[part 1 of 2: packages /CAN3/ISignalGroup to /CAN3/Cluster]
AUTOSAR XML (schema 4-3-0)
package /CAN3/ISignalGroup
  30 x i signal group:
    CAN3_SG_BMS1: i-signal=[CAN3_BMSChckSum_1, CAN3_BMSRolCnct_1, CAN3_HVBPwrAvailChrg, CAN3_HVBPwrAvailChrg30, CAN3_HVBPwrAvailChrg60, CAN3_HVBPwrAvailDchrg, CAN3_HVBPwrAvailDchrg30, CAN3_HVBPwrAvailDchrg60, CAN3_HVBattCurr, CAN3_HVBattVolt], system-signal-group=CAN3_SG_BMS1
    CAN3_SG_BMS2: i-signal=[CAN3_HVInVolt, CAN3_LVBattDet12V, CAN3_OBCDCCurLm, CAN3_OBCDCVoltLm, CAN3_ReChargerStaFromEvcc], system-signal-group=CAN3_SG_BMS2
    CAN3_SG_BMS3: i-signal=[CAN3_ACChrgCurrDis, CAN3_BMS_HVBattCellBalance_Sta, CAN3_Battsystfail_Num, CAN3_CellType, CAN3_HVBChrgPwr, CAN3_HVBChrgPwrTotal, CAN3_HVBDrvPwr, CAN3_HVBDrvPwrTotal, CAN3_HVBFullChrgPwr, CAN3_HVBIsoImpedenceN, CAN3_HVBIsoImpedenceP, CAN3_HVBSOH, CAN3_HVBattPackVolt, CAN3_HVBattSOC, CAN3_HVBattSOCDiff, CAN3_HVBattSOCDis, CAN3_RechrgCyc, CAN3_RemainChrgTime, CAN3_SOC_UseLimit], system-signal-group=CAN3_SG_BMS3
    CAN3_SG_BMS4: i-signal=[CAN3_CellTempAvg, CAN3_HVBCellVoltMax, CAN3_HVBCellVoltMin, CAN3_HVBMTempMax, CAN3_HVBMTempMin, CAN3_MaxCellTemp_Num, CAN3_MaxCellVolt_Num, CAN3_MinCellTemp_Num, CAN3_MinCellVolt_Num, CAN3_Mtemp01, CAN3_Mtemp02, CAN3_Mtemp03, CAN3_Mtemp04, CAN3_Mtemp05, CAN3_Mtemp06, CAN3_Mtemp07, CAN3_Mtemp08, CAN3_Mtemp09, CAN3_Mtemp10, CAN3_Mtemp11, CAN3_Mtemp12, CAN3_Mtemp13, CAN3_Mtemp14, CAN3_Mtemp15, CAN3_Mtemp16, CAN3_Mtemp17, CAN3_Mtemp18, CAN3_Mtemp19, CAN3_Mtemp20], system-signal-group=CAN3_SG_BMS4
    CAN3_SG_BMS6: i-signal=[CAN3_BMSChckSum, CAN3_BMSRolCnct, CAN3_BMS_READY, CAN3_BMS_Warn_1, CAN3_BMS_Warn_2, CAN3_BMS_Warn_3, CAN3_BMS_Warn_4, CAN3_BMS_Warn_5, CAN3_BMS_Warn_6, CAN3_BMS_Warn_7, CAN3_BMS_Warn_8, CAN3_CellUnconsistErr, CAN3_ChrgInLockReq, CAN3_ChrgPlugSta, CAN3_DCChrgSysShockErr, CAN3_DisChrgPlugErr, CAN3_ExtChrgSta, CAN3_HVBCellOvrVoltErr, CAN3_HVBCellOvrVoltWarn, CAN3_HVBCellUdrVoltWarn, CAN3_HVBCellUnbalanErr, CAN3_HVBCellUndrVoltErr, CAN3_HVBChrgErr, CAN3_HVBContactorSta, CAN3_HVBHVILErr, CAN3_HVBOvrChrgCurrErr, CAN3_HVBOvrDchrgCurErr, CAN3_HVBOvrSOCErr, CAN3_HVBOvrTempErr, CAN3_HVBOvrTempWarn, CAN3_HVBOvrVoltErr, CAN3_HVBPrechrgSta, CAN3_HVBPreheatPrecoolSta, CAN3_HVBSOCJumpError, CAN3_HVBShrtChrgCurrErr, CAN3_HVBShrtDischrgCurrErr, CAN3_HVBTempDiffErr, CAN3_HVBUndrSOCErr, CAN3_HVBUndrTempErr, CAN3_HVBUndrTempWarn, CAN3_HVBUndrVoltErr, CAN3_HVBattReady4Pre, CAN3_HVILSta, CAN3_IsoDetSta, CAN3_SystemUncomErr, CAN3_V2LSta], system-signal-group=CAN3_SG_BMS6
    CAN3_SG_BMS7: i-signal=[CAN3_ChrgCurType, CAN3_ChrgLampSta, CAN3_FireDetErr, CAN3_HVBattErr], system-signal-group=CAN3_SG_BMS7
    CAN3_SG_CCU1: i-signal=[CAN3_CS_CCU1, CAN3_DCDCAuxVolt, CAN3_DCDCInVoltInf, CAN3_DCDCPreCompleted, CAN3_OBCDCCurrInf, CAN3_OBCDCVoltInf, CAN3_OBCPreCompleted, CAN3_OBCWakeup4Plugin, CAN3_RC_CCU1], system-signal-group=CAN3_SG_CCU1
    CAN3_SG_CCU2: i-signal=[CAN3_CS_CCU2, CAN3_DCDCEnaSta, CAN3_DCDCFaultSta, CAN3_DCDCReady4Pre, CAN3_DCDCTemp, CAN3_OBCACCurrInf, CAN3_OBCACVoltInf, CAN3_OBCDCP, CAN3_OBCEnaSta, CAN3_OBCFaultSta, CAN3_OBCPluginSta, CAN3_OBCReady4Pre, CAN3_OBCTemp, CAN3_OBCV2LSta, CAN3_OBC_AC_Cur_Lim, CAN3_RC_CCU2, CAN3_ReqOBCV2LEna], system-signal-group=CAN3_SG_CCU2
    CAN3_SG_CCU4: i-signal=[CAN3_DCDCAuxCur, CAN3_DCDCHVCur, CAN3_OBCV2LINVOTP, CAN3_OBCV2LInsuFault, CAN3_OBCV2LVinOVP, CAN3_OBCV2LVinUVP, CAN3_OBCV2LVoutOCP, CAN3_OBCV2LVoutOVP, CAN3_OBCV2LVoutUVP], system-signal-group=CAN3_SG_CCU4
    CAN3_SG_FD_BCM1: i-signal=[CAN3_AllDoorSW, CAN3_AntiTheftSeatFold, CAN3_AntitheftSta, CAN3_BCM_Buzzer_Req, CAN3_BCM_DoorLock_Sta, CAN3_BrakeLamp, CAN3_CTDCtrl, CAN3_CTDLockSW, CAN3_CTDUnlockSW, CAN3_CrashDetd, CAN3_Dimmer, CAN3_DimmerEN, CAN3_DoorLockIND, CAN3_DrDoorSW, CAN3_Fr_ChargingDoorCtrl, CAN3_Fr_FogLamp, CAN3_Fr_Wiper_H, CAN3_Fr_Wiper_L, CAN3_H_Beam, CAN3_HazardSW, CAN3_HoodSW, CAN3_HornCtrl, CAN3_LBSD, CAN3_LDRL, CAN3_LTurnLP, CAN3_L_APM_WdwEnable, CAN3_L_Beam, CAN3_LockSetting, CAN3_MirrorCtrl, CAN3_MirrorDefog, CAN3_PmicBootReason, CAN3_PosLamp, CAN3_PsDoorSW, CAN3_RBSD, CAN3_RDRL, CAN3_RLDoorSW, CAN3_RRDoorSW, CAN3_RTurnLP, CAN3_ReverseLamp, CAN3_RoomLampH, CAN3_RoomLampL, CAN3_Rr_ChargingDoorCtrl, CAN3_Rr_Defog, CAN3_Rr_FogLamp, CAN3_Rr_Wiper, CAN3_TailgateHDSW, CAN3_TailgateRemote, CAN3_Tailgate_SW, CAN3_TrunkRel, CAN3_WasherCtrl, CAN3_WiperFixMode, CAN3_WisrBootReason], system-signal-group=CAN3_SG_FD_BCM1
    CAN3_SG_FD_OTA1: i-signal=[CAN3_OTA_DL_Available, CAN3_OTA_DL_Speed, CAN3_OTA_InVehicle_FW, CAN3_OTA_Lock_Req, CAN3_OTA_MDA_Status, CAN3_OTA_Mode, CAN3_OTA_Network_Type, CAN3_OTA_Progress_Rate, CAN3_OTA_TBOXResetReq, CAN3_OTA_Up_Backcount, CAN3_OTA_Update_Available, CAN3_OTA_Updating_ECU], system-signal-group=CAN3_SG_FD_OTA1
    CAN3_SG_FD_THCM1: i-signal=[CAN3_BatteryMode, CAN3_CCU_ACLampSts, CAN3_CCU_ACMaxLampSts, CAN3_CCU_AutoLampSts, CAN3_CCU_AutoMidLampSts, CAN3_CCU_Dispaly_Request, CAN3_CCU_EcoSts, CAN3_CCU_FrtOnOffLampSts, CAN3_CCU_HEATMaxLampSts, CAN3_CCU_RrOnOffLampSts, CAN3_CCU_SyncLampSts, CAN3_CabinMode, CAN3_EDriveMode, CAN3_FD_AGS_Cmd, CAN3_FD_RecyAuto_Cmd, CAN3_Fr_Coolantflow, CAN3_Fr_Coolanttemp, CAN3_HPThermalRecoveryReq, CAN3_Rr_Coolantflow, CAN3_Rr_Coolanttemp, CAN3_sigAirIntenZon1St, CAN3_sigAirIntenZon3St, CAN3_sigAmbAirT, CAN3_sigCbnAirT, CAN3_sigCbnPTCPwrAct, CAN3_sigCbnSolarLeft, CAN3_sigCbnSolarRight, CAN3_sigClmtCmprPwrAct, CAN3_sigClntTHvBattOut, CAN3_sigDfrstSt, CAN3_sigHvacSt, CAN3_sigRecircSt, CAN3_sigSetTempZon1St, CAN3_sigSetTempZon2St, CAN3_sigSetTempZon3St, CAN3_sigWindDirZon1St, CAN3_sigWindDirZon3St], system-signal-group=CAN3_SG_FD_THCM1
    CAN3_SG_FD_THCM2: i-signal=[CAN3_ACSubMode, CAN3_APTC_ActFrRiPwr, CAN3_BatLoopActWtFlw, CAN3_CCU_CbnPreACWkSts, CAN3_CCU_CbnPreEstimdTi, CAN3_CCU_CbnPreSts, CAN3_CCU_HiVoltageReq, CAN3_CoolgFanActDuty, CAN3_DeiceModReq, CAN3_FD_Blower_Cmd, CAN3_FD_Comp_Cmd, CAN3_FD_EWP1_Cmd, CAN3_FD_EWP2_Cmd, CAN3_FD_EWP3_Cmd, CAN3_FD_EXV1_Cmd, CAN3_FD_EXV2_Cmd, CAN3_FD_FWV_Cmd, CAN3_FD_FrLeAPTCHeatPwr_Cmd, CAN3_FD_FrRiAPTCHeatPwr_Cmd, CAN3_FD_FrWPTCHeatPwr_Cmd, CAN3_FD_RrAPTCHeatPwr_Cmd, CAN3_FD_SOTXV_Cmd, CAN3_FD_SOV1_Cmd, CAN3_FD_SOV2_Cmd, CAN3_FD_SOV3_Cmd, CAN3_FD_TWV_Cmd], system-signal-group=CAN3_SG_FD_THCM2
    CAN3_SG_FD_V2L1: i-signal=[CAN3_Req_OBCV2LEna, CAN3_Req_V2LSwOn, CAN3_Req_V2L_IVI_Popup], system-signal-group=CAN3_SG_FD_V2L1
    CAN3_SG_FD_VCU0: i-signal=[CAN3_EVCCAplusPwrUpReq, CAN3_FDADC12VDet, CAN3_FDADC12VDetAvg, CAN3_FDC_VCU_ActMaxSlideRate_Sta, CAN3_FDC_VCU_AllowMovThd_OTA_Sta, CAN3_FDC_VCU_DTCCarousel_Sta, CAN3_FDC_VCU_ForceP_Cmd, CAN3_FDC_VCU_PwrReq_OTA_Sta, CAN3_FDC_VCU_RWDRDCActive_Sta, CAN3_FDC_VCU_RegenTqLimitEn_Sta, CAN3_FDC_VCU_SlideRegenLimTq_Sta, CAN3_FDC_VCU_VehActSpd_Sta, CAN3_FDC_VCU_VehMalfunLevel_Sta, CAN3_FDC_VMC_ActStESCYaw_Sta, CAN3_FDC_VMC_AntiSpdLimEn_Sta, CAN3_FDC_VMC_LongAcc_Sta, CAN3_Fr_TqSource, CAN3_HVRlyOpFail, CAN3_HVTHCMSysAvail, CAN3_LVBattChrgtimeAct, CAN3_LVBattVoltSta, CAN3_LVChrgHoldTAct, CAN3_LVSilentChrgLv, CAN3_LVSilentChrgReq, CAN3_LVSilentChrgSta, CAN3_MCUActDisFail, CAN3_PMMAllowECUSleep, CAN3_PowerDownFault, CAN3_PowerDownState, CAN3_PowerUpFault, CAN3_PowerUpState, CAN3_PwrDownReq, CAN3_PwrStaConstraint, CAN3_PwrStaONTOIVIPopReq, CAN3_PwrStaONTOIVIPopT, CAN3_PwrStaSelect, CAN3_PwrStaTOSta, CAN3_PwrUpReq, CAN3_Rr_TqSource, CAN3_SchedChgTOSta, CAN3_SilentChkAllowSleep, CAN3_SysAllowReadySta, CAN3_SysPwrSta, CAN3_TCountSta, CAN3_TimerAllowSleep, CAN3_VCUBrkSWSta, CAN3_VCUFLDoorSta, CAN3_VCUFRDoorSta, CAN3_VCURLDoorSta, CAN3_VCURRDoorSta, CAN3_VehHVPwrAvail4THCM], system-signal-group=CAN3_SG_FD_VCU0
    CAN3_SG_FD_VCU1:
      com-based-signal-group-transformations=E2E_PROFILE_01_CAN3_SG_FD_VCU1
      i-signal=[CAN3_ActiveDischReq, CAN3_CS_VCU1, CAN3_CoastDwModeStaChk, CAN3_DCDCEnaReq, CAN3_DCDCVoltSetpoint, CAN3_DemoModeStaChk, CAN3_Dr_SeatSta, CAN3_DynoModeStaChk, CAN3_Fr_ActvDmpDisabReq, CAN3_Fr_MCUEnaReq, CAN3_HVBatCnctReq, CAN3_HVSysReadyToCharge, CAN3_LVChrgFuncStaChk, CAN3_MSA_Crl_Sta, CAN3_PrkReq, CAN3_PwrSta, CAN3_RC_VCU1, CAN3_Rr_ActvDmpDisabReq, CAN3_Rr_MCUEnaReq, CAN3_ShiftGearPosn]
      system-signal-group=CAN3_SG_FD_VCU1
      end-to-end-transformation-i-signal-props{transformer=Technology_E2E_PROFILE_01_CAN3_SG_FD_VCU1, data-ids=13815, data-length=64}
    CAN3_SG_FD_VCU2: i-signal=[CAN3_CS_VCU2_CAN1, CAN3_Fr_IdcMax, CAN3_Fr_IdcMin, CAN3_Fr_TMTqReq, CAN3_Fr_TorqMax, CAN3_Fr_TorqMin, CAN3_Fr_UdcMax, CAN3_Fr_UdcMin, CAN3_RC_VCU2_CAN1, CAN3_Rr_IdcMax, CAN3_Rr_IdcMin, CAN3_Rr_TMTqReq, CAN3_Rr_TorqMax, CAN3_Rr_TorqMin, CAN3_Rr_UdcMax, CAN3_Rr_UdcMin], system-signal-group=CAN3_SG_FD_VCU2
    CAN3_SG_MCU_F1: i-signal=[CAN3_Fr_ActvDmpDisabSta, CAN3_Fr_EDUDrtSta, CAN3_Fr_EDUOpratingSta, CAN3_Fr_EDURealTMTq, CAN3_Fr_EDURotateDirction, CAN3_Fr_EDUTqReqFbk, CAN3_Fr_MCU1Chksum, CAN3_Fr_MCU1RolCnt, CAN3_Fr_MCUBAT, CAN3_Fr_MCUDCBusCurr, CAN3_Fr_MCUDCBusVolt, CAN3_Fr_MCUDischrgSta, CAN3_Fr_MCUEnaSta, CAN3_Fr_MCUErr, CAN3_Fr_MCUIGN_sta, CAN3_Fr_MCUReady, CAN3_Fr_MCUReady4Pre, CAN3_Fr_MCUSysSta, CAN3_Fr_MCUTemp, CAN3_Fr_MotorAvailTq, CAN3_Fr_RegenAvailTq, CAN3_Fr_Reserved_bits, CAN3_Fr_TMSpd, CAN3_Fr_TMTemp, CAN3_Fr_TMid, CAN3_Fr_TMiq, CAN3_MCUWarn_F], system-signal-group=CAN3_SG_MCU_F1
    CAN3_SG_MCU_F2: i-signal=[CAN3_Fr_CoolanttempReq, CAN3_Fr_EOP_SpdSet, CAN3_Fr_Failcode1, CAN3_Fr_Failcode2, CAN3_Fr_Failcodehistory1, CAN3_Fr_Failcodehistory2, CAN3_Fr_LLCTemp, CAN3_Fr_LLCflowReq, CAN3_Fr_MCU2Chksum, CAN3_Fr_MCU2RolCnt, CAN3_Fr_MCUTempWarn, CAN3_Fr_TMTempWarn, CAN3_MCU_F_ResetCnt_Sta], system-signal-group=CAN3_SG_MCU_F2
    CAN3_SG_MCU_R1: i-signal=[CAN3_MCUWarn_R, CAN3_Rr_ActvDmpDisabSta, CAN3_Rr_EDUDrtSta, CAN3_Rr_EDUOpratingSta, CAN3_Rr_EDURealTMTq, CAN3_Rr_EDURotateDirction, CAN3_Rr_EDUTqReqFbk, CAN3_Rr_MCU1Chksum, CAN3_Rr_MCU1RolCnt, CAN3_Rr_MCUBAT, CAN3_Rr_MCUDCBusCurr, CAN3_Rr_MCUDCBusVolt, CAN3_Rr_MCUDischrgSta, CAN3_Rr_MCUEnaSta, CAN3_Rr_MCUErr, CAN3_Rr_MCUIGN_sta, CAN3_Rr_MCUReady, CAN3_Rr_MCUReady4Pre, CAN3_Rr_MCUSysSta, CAN3_Rr_MCUTemp, CAN3_Rr_MotorAvailTq, CAN3_Rr_RegenAvailTq, CAN3_Rr_Reserved_bits, CAN3_Rr_TMSpd, CAN3_Rr_TMTemp, CAN3_Rr_TMid, CAN3_Rr_TMiq], system-signal-group=CAN3_SG_MCU_R1
    CAN3_SG_MCU_R2: i-signal=[CAN3_MCU_R_ResetCnt_Sta, CAN3_Rr_CoolanttempReq, CAN3_Rr_EOP_SpdSet, CAN3_Rr_Failcode1, CAN3_Rr_Failcode2, CAN3_Rr_Failcodehistory1, CAN3_Rr_Failcodehistory2, CAN3_Rr_LLCTemp, CAN3_Rr_LLCflowReq, CAN3_Rr_MCU2Chksum, CAN3_Rr_MCU2RolCnt, CAN3_Rr_MCUTempWarn, CAN3_Rr_TMTempWarn], system-signal-group=CAN3_SG_MCU_R2
    CAN3_SG_Shifter1: i-signal=[CAN3_Shifter_CRC8, CAN3_Shifter_Fail_sta, CAN3_Shifter_Handle_Cmd, CAN3_Shifter_RC], system-signal-group=CAN3_SG_Shifter1
    CAN3_SG_XNMm_BMS: i-signal=[CAN3_NM_BMS_Active_WU, CAN3_NM_BMS_CSB, CAN3_NM_BMS_ERROR_State, CAN3_NM_BMS_Node_ID, CAN3_NM_BMS_PNI, CAN3_NM_BMS_Rpt_Msg_Req], system-signal-group=CAN3_SG_XNMm_BMS
    CAN3_SG_XNMm_CCU: i-signal=[CAN3_NM_CCU_Active_WU, CAN3_NM_CCU_CSB, CAN3_NM_CCU_ERROR_State, CAN3_NM_CCU_Node_ID, CAN3_NM_CCU_PNI, CAN3_NM_CCU_Rpt_Msg_Req], system-signal-group=CAN3_SG_XNMm_CCU
    CAN3_SG_XNMm_EOP_F: i-signal=[CAN3_NM_EOP_F_Active_WU, CAN3_NM_EOP_F_CSB, CAN3_NM_EOP_F_ERROR_State, CAN3_NM_EOP_F_Node_ID, CAN3_NM_EOP_F_PNI, CAN3_NM_EOP_F_Rpt_Msg_Req], system-signal-group=CAN3_SG_XNMm_EOP_F
    CAN3_SG_XNMm_EOP_R: i-signal=[CAN3_NM_EOP_R_Active_WU, CAN3_NM_EOP_R_CSB, CAN3_NM_EOP_R_ERROR_State, CAN3_NM_EOP_R_Node_ID, CAN3_NM_EOP_R_PNI, CAN3_NM_EOP_R_Rpt_Msg_Req], system-signal-group=CAN3_SG_XNMm_EOP_R
    CAN3_SG_XNMm_FUSION: i-signal=[CAN3_NM_FUSION_Active_WU, CAN3_NM_FUSION_CSB, CAN3_NM_FUSION_ERROR_State, CAN3_NM_FUSION_Node_ID, CAN3_NM_FUSION_PNI, CAN3_NM_FUSION_Rpt_Msg_Req], system-signal-group=CAN3_SG_XNMm_FUSION
    CAN3_SG_XNMm_MCU_F: i-signal=[CAN3_NM_MCU_F_Active_WU, CAN3_NM_MCU_F_CSB, CAN3_NM_MCU_F_ERROR_State, CAN3_NM_MCU_F_Node_ID, CAN3_NM_MCU_F_PNI, CAN3_NM_MCU_F_Rpt_Msg_Req], system-signal-group=CAN3_SG_XNMm_MCU_F
    CAN3_SG_XNMm_MCU_R: i-signal=[CAN3_NM_MCU_R_Active_WU, CAN3_NM_MCU_R_CSB, CAN3_NM_MCU_R_ERROR_State, CAN3_NM_MCU_R_Node_ID, CAN3_NM_MCU_R_PNI, CAN3_NM_MCU_R_Rpt_Msg_Req], system-signal-group=CAN3_SG_XNMm_MCU_R
    CAN3_SG_XNMm_Shifter: i-signal=[CAN3_NM_Shifter_Active_WU, CAN3_NM_Shifter_CSB, CAN3_NM_Shifter_ERROR_State, CAN3_NM_Shifter_Node_ID, CAN3_NM_Shifter_PNI, CAN3_NM_Shifter_Rpt_Msg_Req], system-signal-group=CAN3_SG_XNMm_Shifter
package /CAN3/Cluster
  can cluster CAN3: baudrate=500, can-fd-baudrate=2000
    can physical channel CAN3: comm-connectors=ConnCAN3
      frame CAN3_BMS1: id 0x171, frame-length=16, can-addressing-mode=STANDARD, can-fd-frame-support=true, can-frame-rx-behavior=CAN-FD, can-frame-tx-behavior=CAN-FD
        pdu CAN3_BMS1: length=16, minimum-delay=0.0, transmission-mode-true-timing=cyclic-timing=time-period=0.01, unused-bit-pattern=0
          mapping CAN3_SG_BMS1: i-signal-group=CAN3_SG_BMS1, start-position=0, transfer-property=PENDING
          signal CAN3_BMSChckSum_1: start 7, 8 bit, big-endian, i-signal-type=PRIMITIVE, init-value=constant-reference=Init_CAN3_BMSChckSum_1, base-type=uint8, implementation-data-type=uint8, transfer-property=PENDING
          signal CAN3_BMSRolCnct_1: start 15, 4 bit, big-endian, i-signal-type=PRIMITIVE, init-value=constant-reference=Init_CAN3_BMSRolCnct_1, base-type=uint8, implementation-data-type=uint8, transfer-property=PENDING
          signal CAN3_HVBPwrAvailChrg: start 91, 12 bit, big-endian, i-signal-type=PRIMITIVE, init-value=constant-reference=Init_CAN3_HVBPwrAvailChrg, base-type=uint16, implementation-data-type=uint16, transfer-property=PENDING
          signal CAN3_HVBPwrAvailChrg30: start 115, 12 bit, big-endian, i-signal-type=PRIMITIVE, init-value=constant-reference=Init_CAN3_HVBPwrAvailChrg30, base-type=uint16, implementation-data-type=uint16, transfer-property=PENDING
          signal CAN3_HVBPwrAvailChrg60: start 67, 12 bit, big-endian, i-signal-type=PRIMITIVE, init-value=constant-reference=Init_CAN3_HVBPwrAvailChrg60, base-type=uint16, implementation-data-type=uint16, transfer-property=PENDING
          signal CAN3_HVBPwrAvailDchrg: start 87, 12 bit, big-endian, i-signal-type=PRIMITIVE, init-value=constant-reference=Init_CAN3_HVBPwrAvailDchrg, base-type=uint16, implementation-data-type=uint16, transfer-property=PENDING
          signal CAN3_HVBPwrAvailDchrg30: start 111, 12 bit, big-endian, i-signal-type=PRIMITIVE, init-value=constant-reference=Init_CAN3_HVBPwrAvailDchrg30, base-type=uint16, implementation-data-type=uint16, transfer-property=PENDING
          signal CAN3_HVBPwrAvailDchrg60: start 63, 12 bit, big-endian, i-signal-type=PRIMITIVE, init-value=constant-reference=Init_CAN3_HVBPwrAvailDchrg60, base-type=uint16, implementation-data-type=uint16, transfer-property=PENDING
          signal CAN3_HVBattCurr: start 46, 15 bit, big-endian, i-signal-type=PRIMITIVE, init-value=constant-reference=Init_CAN3_HVBattCurr, base-type=uint16, implementation-data-type=uint16, transfer-property=PENDING
          signal CAN3_HVBattVolt: start 28, 13 bit, big-endian, i-signal-type=PRIMITIVE, init-value=constant-reference=Init_CAN3_HVBattVolt, base-type=uint16, implementation-data-type=uint16, transfer-property=PENDING
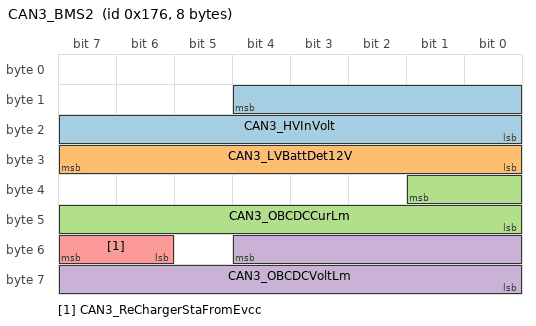
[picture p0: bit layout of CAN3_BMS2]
      frame CAN3_BMS2: id 0x176, frame-length=8, can-addressing-mode=STANDARD, can-fd-frame-support=true, can-frame-rx-behavior=CAN-FD, can-frame-tx-behavior=CAN-FD
        pdu CAN3_BMS2: length=8, minimum-delay=0.0, transmission-mode-true-timing={cyclic-timing=time-period=0.1, event-controlled-timing={number-of-repetitions=0, repetition-period=0.01}}, unused-bit-pattern=0
          mapping CAN3_SG_BMS2: i-signal-group=CAN3_SG_BMS2, start-position=0, transfer-property=TRIGGERED-ON-CHANGE
          signal CAN3_HVInVolt: start 12, 13 bit, big-endian, i-signal-type=PRIMITIVE, init-value=constant-reference=Init_CAN3_HVInVolt, base-type=uint16, implementation-data-type=uint16, transfer-property=PENDING
          signal CAN3_LVBattDet12V: start 31, 8 bit, big-endian, i-signal-type=PRIMITIVE, init-value=constant-reference=Init_CAN3_LVBattDet12V, base-type=uint8, implementation-data-type=uint8, transfer-property=PENDING
          signal CAN3_OBCDCCurLm: start 33, 10 bit, big-endian, i-signal-type=PRIMITIVE, init-value=constant-reference=Init_CAN3_OBCDCCurLm, base-type=uint16, implementation-data-type=uint16, transfer-property=PENDING
          signal CAN3_OBCDCVoltLm: start 52, 13 bit, big-endian, i-signal-type=PRIMITIVE, init-value=constant-reference=Init_CAN3_OBCDCVoltLm, base-type=uint16, implementation-data-type=uint16, transfer-property=PENDING
          signal CAN3_ReChargerStaFromEvcc: start 55, 2 bit, big-endian, i-signal-type=PRIMITIVE, init-value=constant-reference=Init_CAN3_ReChargerStaFromEvcc, base-type=uint8, implementation-data-type=uint8, transfer-property=TRIGGERED-ON-CHANGE
      frame CAN3_BMS3: id 0x329, frame-length=32, can-addressing-mode=STANDARD, can-fd-frame-support=true, can-frame-rx-behavior=CAN-FD, can-frame-tx-behavior=CAN-FD
        pdu CAN3_BMS3: length=32, minimum-delay=0.0, transmission-mode-true-timing=cyclic-timing=time-period=1, unused-bit-pattern=0
          mapping CAN3_SG_BMS3: i-signal-group=CAN3_SG_BMS3, start-position=0, transfer-property=PENDING
          signal CAN3_ACChrgCurrDis: start 86, 15 bit, big-endian, i-signal-type=PRIMITIVE, init-value=constant-reference=Init_CAN3_ACChrgCurrDis, base-type=uint16, implementation-data-type=uint16, transfer-property=PENDING
          signal CAN3_BMS_HVBattCellBalance_Sta: start 200, 1 bit, big-endian, i-signal-type=PRIMITIVE, init-value=constant-reference=Init_CAN3_BMS_HVBattCellBalance_Sta, base-type=uint8, implementation-data-type=uint8, transfer-property=PENDING
          signal CAN3_Battsystfail_Num: start 127, 8 bit, big-endian, i-signal-type=PRIMITIVE, init-value=constant-reference=Init_CAN3_Battsystfail_Num, base-type=uint8, implementation-data-type=uint8, transfer-property=PENDING
          signal CAN3_CellType: start 101, 4 bit, big-endian, i-signal-type=PRIMITIVE, init-value=constant-reference=Init_CAN3_CellType, base-type=uint8, implementation-data-type=uint8, transfer-property=PENDING
          signal CAN3_HVBChrgPwr: start 223, 10 bit, big-endian, i-signal-type=PRIMITIVE, init-value=constant-reference=Init_CAN3_HVBChrgPwr, base-type=uint16, implementation-data-type=uint16, transfer-property=PENDING
          signal CAN3_HVBChrgPwrTotal: start 57, 18 bit, big-endian, i-signal-type=PRIMITIVE, init-value=constant-reference=Init_CAN3_HVBChrgPwrTotal, base-type=uint32, implementation-data-type=uint32, transfer-property=PENDING
          signal CAN3_HVBDrvPwr: start 199, 10 bit, big-endian, i-signal-type=PRIMITIVE, init-value=constant-reference=Init_CAN3_HVBDrvPwr, base-type=uint16, implementation-data-type=uint16, transfer-property=PENDING
          signal CAN3_HVBDrvPwrTotal: start 33, 18 bit, big-endian, i-signal-type=PRIMITIVE, init-value=constant-reference=Init_CAN3_HVBDrvPwrTotal, base-type=uint32, implementation-data-type=uint32, transfer-property=PENDING
          signal CAN3_HVBFullChrgPwr: start 177, 10 bit, big-endian, i-signal-type=PRIMITIVE, init-value=constant-reference=Init_CAN3_HVBFullChrgPwr, base-type=uint16, implementation-data-type=uint16, transfer-property=PENDING
          signal CAN3_HVBIsoImpedenceN: start 134, 15 bit, big-endian, i-signal-type=PRIMITIVE, init-value=constant-reference=Init_CAN3_HVBIsoImpedenceN, base-type=uint16, implementation-data-type=uint16, transfer-property=PENDING
          signal CAN3_HVBIsoImpedenceP: start 150, 15 bit, big-endian, i-signal-type=PRIMITIVE, init-value=constant-reference=Init_CAN3_HVBIsoImpedenceP, base-type=uint16, implementation-data-type=uint16, transfer-property=PENDING
          signal CAN3_HVBSOH: start 167, 8 bit, big-endian, i-signal-type=PRIMITIVE, init-value=constant-reference=Init_CAN3_HVBSOH, base-type=uint8, implementation-data-type=uint8, transfer-property=PENDING
          signal CAN3_HVBattPackVolt: start 228, 13 bit, big-endian, i-signal-type=PRIMITIVE, init-value=constant-reference=Init_CAN3_HVBattPackVolt, base-type=uint16, implementation-data-type=uint16, transfer-property=PENDING
          signal CAN3_HVBattSOC: start 247, 8 bit, big-endian, i-signal-type=PRIMITIVE, init-value=constant-reference=Init_CAN3_HVBattSOC, base-type=uint8, implementation-data-type=uint8, transfer-property=PENDING
          signal CAN3_HVBattSOCDiff: start 213, 6 bit, big-endian, i-signal-type=PRIMITIVE, init-value=constant-reference=Init_CAN3_HVBattSOCDiff, base-type=uint8, implementation-data-type=uint8, transfer-property=PENDING
          signal CAN3_HVBattSOCDis: start 255, 8 bit, big-endian, i-signal-type=PRIMITIVE, init-value=constant-reference=Init_CAN3_HVBattSOCDis, base-type=uint8, implementation-data-type=uint8, transfer-property=PENDING
          signal CAN3_RechrgCyc: start 97, 18 bit, big-endian, i-signal-type=PRIMITIVE, init-value=constant-reference=Init_CAN3_RechrgCyc, base-type=uint32, implementation-data-type=uint32, transfer-property=PENDING
          signal CAN3_RemainChrgTime: start 175, 12 bit, big-endian, i-signal-type=PRIMITIVE, init-value=constant-reference=Init_CAN3_RemainChrgTime, base-type=uint16, implementation-data-type=uint16, transfer-property=PENDING
          signal CAN3_SOC_UseLimit: start 215, 2 bit, big-endian, i-signal-type=PRIMITIVE, init-value=constant-reference=Init_CAN3_SOC_UseLimit, base-type=uint8, implementation-data-type=uint8, transfer-property=PENDING
      frame CAN3_BMS4: id 0x3E0, frame-length=48, can-addressing-mode=STANDARD, can-fd-frame-support=true, can-frame-rx-behavior=CAN-FD, can-frame-tx-behavior=CAN-FD
        pdu CAN3_BMS4: length=48, minimum-delay=0.0, transmission-mode-true-timing=cyclic-timing=time-period=0.1, unused-bit-pattern=0
          mapping CAN3_SG_BMS4: i-signal-group=CAN3_SG_BMS4, start-position=0, transfer-property=PENDING
          signal CAN3_CellTempAvg: start 351, 8 bit, big-endian, i-signal-type=PRIMITIVE, init-value=constant-reference=Init_CAN3_CellTempAvg, base-type=uint8, implementation-data-type=uint8, transfer-property=PENDING
          signal CAN3_HVBCellVoltMax: start 375, 16 bit, big-endian, i-signal-type=PRIMITIVE, init-value=constant-reference=Init_CAN3_HVBCellVoltMax, base-type=uint16, implementation-data-type=uint16, transfer-property=PENDING
          signal CAN3_HVBCellVoltMin: start 359, 16 bit, big-endian, i-signal-type=PRIMITIVE, init-value=constant-reference=Init_CAN3_HVBCellVoltMin, base-type=uint16, implementation-data-type=uint16, transfer-property=PENDING
          signal CAN3_HVBMTempMax: start 311, 8 bit, big-endian, i-signal-type=PRIMITIVE, init-value=constant-reference=Init_CAN3_HVBMTempMax, base-type=uint8, implementation-data-type=uint8, transfer-property=PENDING
          signal CAN3_HVBMTempMin: start 303, 8 bit, big-endian, i-signal-type=PRIMITIVE, init-value=constant-reference=Init_CAN3_HVBMTempMin, base-type=uint8, implementation-data-type=uint8, transfer-property=PENDING
          signal CAN3_MaxCellTemp_Num: start 327, 8 bit, big-endian, i-signal-type=PRIMITIVE, init-value=constant-reference=Init_CAN3_MaxCellTemp_Num, base-type=uint8, implementation-data-type=uint8, transfer-property=PENDING
          signal CAN3_MaxCellVolt_Num: start 343, 8 bit, big-endian, i-signal-type=PRIMITIVE, init-value=constant-reference=Init_CAN3_MaxCellVolt_Num, base-type=uint8, implementation-data-type=uint8, transfer-property=PENDING
          signal CAN3_MinCellTemp_Num: start 319, 8 bit, big-endian, i-signal-type=PRIMITIVE, init-value=constant-reference=Init_CAN3_MinCellTemp_Num, base-type=uint8, implementation-data-type=uint8, transfer-property=PENDING
          signal CAN3_MinCellVolt_Num: start 335, 8 bit, big-endian, i-signal-type=PRIMITIVE, init-value=constant-reference=Init_CAN3_MinCellVolt_Num, base-type=uint8, implementation-data-type=uint8, transfer-property=PENDING
          signal CAN3_Mtemp01: start 119, 8 bit, big-endian, i-signal-type=PRIMITIVE, init-value=constant-reference=Init_CAN3_Mtemp01, base-type=uint8, implementation-data-type=uint8, transfer-property=PENDING
          signal CAN3_Mtemp02: start 111, 8 bit, big-endian, i-signal-type=PRIMITIVE, init-value=constant-reference=Init_CAN3_Mtemp02, base-type=uint8, implementation-data-type=uint8, transfer-property=PENDING
          signal CAN3_Mtemp03: start 103, 8 bit, big-endian, i-signal-type=PRIMITIVE, init-value=constant-reference=Init_CAN3_Mtemp03, base-type=uint8, implementation-data-type=uint8, transfer-property=PENDING
          signal CAN3_Mtemp04: start 95, 8 bit, big-endian, i-signal-type=PRIMITIVE, init-value=constant-reference=Init_CAN3_Mtemp04, base-type=uint8, implementation-data-type=uint8, transfer-property=PENDING
          signal CAN3_Mtemp05: start 87, 8 bit, big-endian, i-signal-type=PRIMITIVE, init-value=constant-reference=Init_CAN3_Mtemp05, base-type=uint8, implementation-data-type=uint8, transfer-property=PENDING
          signal CAN3_Mtemp06: start 79, 8 bit, big-endian, i-signal-type=PRIMITIVE, init-value=constant-reference=Init_CAN3_Mtemp06, base-type=uint8, implementation-data-type=uint8, transfer-property=PENDING
          signal CAN3_Mtemp07: start 71, 8 bit, big-endian, i-signal-type=PRIMITIVE, init-value=constant-reference=Init_CAN3_Mtemp07, base-type=uint8, implementation-data-type=uint8, transfer-property=PENDING
          signal CAN3_Mtemp08: start 63, 8 bit, big-endian, i-signal-type=PRIMITIVE, init-value=constant-reference=Init_CAN3_Mtemp08, base-type=uint8, implementation-data-type=uint8, transfer-property=PENDING
          signal CAN3_Mtemp09: start 55, 8 bit, big-endian, i-signal-type=PRIMITIVE, init-value=constant-reference=Init_CAN3_Mtemp09, base-type=uint8, implementation-data-type=uint8, transfer-property=PENDING
          signal CAN3_Mtemp10: start 47, 8 bit, big-endian, i-signal-type=PRIMITIVE, init-value=constant-reference=Init_CAN3_Mtemp10, base-type=uint8, implementation-data-type=uint8, transfer-property=PENDING
          signal CAN3_Mtemp11: start 39, 8 bit, big-endian, i-signal-type=PRIMITIVE, init-value=constant-reference=Init_CAN3_Mtemp11, base-type=uint8, implementation-data-type=uint8, transfer-property=PENDING
          signal CAN3_Mtemp12: start 31, 8 bit, big-endian, i-signal-type=PRIMITIVE, init-value=constant-reference=Init_CAN3_Mtemp12, base-type=uint8, implementation-data-type=uint8, transfer-property=PENDING
          signal CAN3_Mtemp13: start 23, 8 bit, big-endian, i-signal-type=PRIMITIVE, init-value=constant-reference=Init_CAN3_Mtemp13, base-type=uint8, implementation-data-type=uint8, transfer-property=PENDING
          signal CAN3_Mtemp14: start 15, 8 bit, big-endian, i-signal-type=PRIMITIVE, init-value=constant-reference=Init_CAN3_Mtemp14, base-type=uint8, implementation-data-type=uint8, transfer-property=PENDING
          signal CAN3_Mtemp15: start 7, 8 bit, big-endian, i-signal-type=PRIMITIVE, init-value=constant-reference=Init_CAN3_Mtemp15, base-type=uint8, implementation-data-type=uint8, transfer-property=PENDING
          signal CAN3_Mtemp16: start 159, 8 bit, big-endian, i-signal-type=PRIMITIVE, init-value=constant-reference=Init_CAN3_Mtemp16, base-type=uint8, implementation-data-type=uint8, transfer-property=PENDING
          signal CAN3_Mtemp17: start 151, 8 bit, big-endian, i-signal-type=PRIMITIVE, init-value=constant-reference=Init_CAN3_Mtemp17, base-type=uint8, implementation-data-type=uint8, transfer-property=PENDING
          signal CAN3_Mtemp18: start 143, 8 bit, big-endian, i-signal-type=PRIMITIVE, init-value=constant-reference=Init_CAN3_Mtemp18, base-type=uint8, implementation-data-type=uint8, transfer-property=PENDING
          signal CAN3_Mtemp19: start 135, 8 bit, big-endian, i-signal-type=PRIMITIVE, init-value=constant-reference=Init_CAN3_Mtemp19, base-type=uint8, implementation-data-type=uint8, transfer-property=PENDING
          signal CAN3_Mtemp20: start 127, 8 bit, big-endian, i-signal-type=PRIMITIVE, init-value=constant-reference=Init_CAN3_Mtemp20, base-type=uint8, implementation-data-type=uint8, transfer-property=PENDING
      frame CAN3_BMS6: id 0x17A, frame-length=12, can-addressing-mode=STANDARD, can-fd-frame-support=true, can-frame-rx-behavior=CAN-FD, can-frame-tx-behavior=CAN-FD
        pdu CAN3_BMS6: length=12, minimum-delay=0.0, transmission-mode-true-timing={cyclic-timing=time-period=0.1, event-controlled-timing={number-of-repetitions=0, repetition-period=0.01}}, unused-bit-pattern=0
          mapping CAN3_SG_BMS6: i-signal-group=CAN3_SG_BMS6, start-position=0, transfer-property=TRIGGERED-ON-CHANGE
          signal CAN3_BMSChckSum: start 7, 8 bit, big-endian, i-signal-type=PRIMITIVE, init-value=constant-reference=Init_CAN3_BMSChckSum, base-type=uint8, implementation-data-type=uint8, transfer-property=PENDING
          signal CAN3_BMSRolCnct: start 15, 4 bit, big-endian, i-signal-type=PRIMITIVE, init-value=constant-reference=Init_CAN3_BMSRolCnct, base-type=uint8, implementation-data-type=uint8, transfer-property=PENDING
          signal CAN3_BMS_READY: start 65, 1 bit, big-endian, i-signal-type=PRIMITIVE, init-value=constant-reference=Init_CAN3_BMS_READY, base-type=uint8, implementation-data-type=uint8, transfer-property=TRIGGERED-ON-CHANGE
          signal CAN3_BMS_Warn_1: start 88, 1 bit, big-endian, i-signal-type=PRIMITIVE, init-value=constant-reference=Init_CAN3_BMS_Warn_1, base-type=uint8, implementation-data-type=uint8, transfer-property=TRIGGERED-ON-CHANGE
          signal CAN3_BMS_Warn_2: start 89, 1 bit, big-endian, i-signal-type=PRIMITIVE, init-value=constant-reference=Init_CAN3_BMS_Warn_2, base-type=uint8, implementation-data-type=uint8, transfer-property=TRIGGERED-ON-CHANGE
          signal CAN3_BMS_Warn_3: start 90, 1 bit, big-endian, i-signal-type=PRIMITIVE, init-value=constant-reference=Init_CAN3_BMS_Warn_3, base-type=uint8, implementation-data-type=uint8, transfer-property=TRIGGERED-ON-CHANGE
          signal CAN3_BMS_Warn_4: start 91, 1 bit, big-endian, i-signal-type=PRIMITIVE, init-value=constant-reference=Init_CAN3_BMS_Warn_4, base-type=uint8, implementation-data-type=uint8, transfer-property=TRIGGERED-ON-CHANGE
          signal CAN3_BMS_Warn_5: start 92, 1 bit, big-endian, i-signal-type=PRIMITIVE, init-value=constant-reference=Init_CAN3_BMS_Warn_5, base-type=uint8, implementation-data-type=uint8, transfer-property=TRIGGERED-ON-CHANGE
          signal CAN3_BMS_Warn_6: start 93, 1 bit, big-endian, i-signal-type=PRIMITIVE, init-value=constant-reference=Init_CAN3_BMS_Warn_6, base-type=uint8, implementation-data-type=uint8, transfer-property=TRIGGERED-ON-CHANGE
          signal CAN3_BMS_Warn_7: start 94, 1 bit, big-endian, i-signal-type=PRIMITIVE, init-value=constant-reference=Init_CAN3_BMS_Warn_7, base-type=uint8, implementation-data-type=uint8, transfer-property=TRIGGERED-ON-CHANGE
          signal CAN3_BMS_Warn_8: start 95, 1 bit, big-endian, i-signal-type=PRIMITIVE, init-value=constant-reference=Init_CAN3_BMS_Warn_8, base-type=uint8, implementation-data-type=uint8, transfer-property=TRIGGERED-ON-CHANGE
          signal CAN3_CellUnconsistErr: start 50, 1 bit, big-endian, i-signal-type=PRIMITIVE, init-value=constant-reference=Init_CAN3_CellUnconsistErr, base-type=uint8, implementation-data-type=uint8, transfer-property=TRIGGERED-ON-CHANGE
          signal CAN3_ChrgInLockReq: start 45, 2 bit, big-endian, i-signal-type=PRIMITIVE, init-value=constant-reference=Init_CAN3_ChrgInLockReq, base-type=uint8, implementation-data-type=uint8, transfer-property=TRIGGERED-ON-CHANGE
          signal CAN3_ChrgPlugSta: start 59, 2 bit, big-endian, i-signal-type=PRIMITIVE, init-value=constant-reference=Init_CAN3_ChrgPlugSta, base-type=uint8, implementation-data-type=uint8, transfer-property=TRIGGERED-ON-CHANGE
          signal CAN3_DCChrgSysShockErr: start 64, 1 bit, big-endian, i-signal-type=PRIMITIVE, init-value=constant-reference=Init_CAN3_DCChrgSysShockErr, base-type=uint8, implementation-data-type=uint8, transfer-property=TRIGGERED-ON-CHANGE
          signal CAN3_DisChrgPlugErr: start 47, 2 bit, big-endian, i-signal-type=PRIMITIVE, init-value=constant-reference=Init_CAN3_DisChrgPlugErr, base-type=uint8, implementation-data-type=uint8, transfer-property=TRIGGERED-ON-CHANGE
          signal CAN3_ExtChrgSta: start 61, 2 bit, big-endian, i-signal-type=PRIMITIVE, init-value=constant-reference=Init_CAN3_ExtChrgSta, base-type=uint8, implementation-data-type=uint8, transfer-property=TRIGGERED-ON-CHANGE
          signal CAN3_HVBCellOvrVoltErr: start 40, 1 bit, big-endian, i-signal-type=PRIMITIVE, init-value=constant-reference=Init_CAN3_HVBCellOvrVoltErr, base-type=uint8, implementation-data-type=uint8, transfer-property=TRIGGERED-ON-CHANGE
          signal CAN3_HVBCellOvrVoltWarn: start 53, 2 bit, big-endian, i-signal-type=PRIMITIVE, init-value=constant-reference=Init_CAN3_HVBCellOvrVoltWarn, base-type=uint8, implementation-data-type=uint8, transfer-property=TRIGGERED-ON-CHANGE
          signal CAN3_HVBCellUdrVoltWarn: start 55, 2 bit, big-endian, i-signal-type=PRIMITIVE, init-value=constant-reference=Init_CAN3_HVBCellUdrVoltWarn, base-type=uint8, implementation-data-type=uint8, transfer-property=TRIGGERED-ON-CHANGE
          signal CAN3_HVBCellUnbalanErr: start 42, 1 bit, big-endian, i-signal-type=PRIMITIVE, init-value=constant-reference=Init_CAN3_HVBCellUnbalanErr, base-type=uint8, implementation-data-type=uint8, transfer-property=TRIGGERED-ON-CHANGE
          signal CAN3_HVBCellUndrVoltErr: start 41, 1 bit, big-endian, i-signal-type=PRIMITIVE, init-value=constant-reference=Init_CAN3_HVBCellUndrVoltErr, base-type=uint8, implementation-data-type=uint8, transfer-property=TRIGGERED-ON-CHANGE
          signal CAN3_HVBChrgErr: start 39, 8 bit, big-endian, i-signal-type=PRIMITIVE, init-value=constant-reference=Init_CAN3_HVBChrgErr, base-type=uint8, implementation-data-type=uint8, transfer-property=TRIGGERED-ON-CHANGE
          signal CAN3_HVBContactorSta: start 66, 1 bit, big-endian, i-signal-type=PRIMITIVE, init-value=constant-reference=Init_CAN3_HVBContactorSta, base-type=uint8, implementation-data-type=uint8, transfer-property=TRIGGERED-ON-CHANGE
          signal CAN3_HVBHVILErr: start 79, 1 bit, big-endian, i-signal-type=PRIMITIVE, init-value=constant-reference=Init_CAN3_HVBHVILErr, base-type=uint8, implementation-data-type=uint8, transfer-property=TRIGGERED-ON-CHANGE
          signal CAN3_HVBOvrChrgCurrErr: start 72, 1 bit, big-endian, i-signal-type=PRIMITIVE, init-value=constant-reference=Init_CAN3_HVBOvrChrgCurrErr, base-type=uint8, implementation-data-type=uint8, transfer-property=TRIGGERED-ON-CHANGE
          signal CAN3_HVBOvrDchrgCurErr: start 73, 1 bit, big-endian, i-signal-type=PRIMITIVE, init-value=constant-reference=Init_CAN3_HVBOvrDchrgCurErr, base-type=uint8, implementation-data-type=uint8, transfer-property=TRIGGERED-ON-CHANGE
          signal CAN3_HVBOvrSOCErr: start 76, 1 bit, big-endian, i-signal-type=PRIMITIVE, init-value=constant-reference=Init_CAN3_HVBOvrSOCErr, base-type=uint8, implementation-data-type=uint8, transfer-property=TRIGGERED-ON-CHANGE
          signal CAN3_HVBOvrTempErr: start 74, 1 bit, big-endian, i-signal-type=PRIMITIVE, init-value=constant-reference=Init_CAN3_HVBOvrTempErr, base-type=uint8, implementation-data-type=uint8, transfer-property=TRIGGERED-ON-CHANGE
          signal CAN3_HVBOvrTempWarn: start 81, 2 bit, big-endian, i-signal-type=PRIMITIVE, init-value=constant-reference=Init_CAN3_HVBOvrTempWarn, base-type=uint8, implementation-data-type=uint8, transfer-property=TRIGGERED-ON-CHANGE
          signal CAN3_HVBOvrVoltErr: start 84, 1 bit, big-endian, i-signal-type=PRIMITIVE, init-value=constant-reference=Init_CAN3_HVBOvrVoltErr, base-type=uint8, implementation-data-type=uint8, transfer-property=TRIGGERED-ON-CHANGE
          signal CAN3_HVBPrechrgSta: start 69, 2 bit, big-endian, i-signal-type=PRIMITIVE, init-value=constant-reference=Init_CAN3_HVBPrechrgSta, base-type=uint8, implementation-data-type=uint8, transfer-property=TRIGGERED-ON-CHANGE
          signal CAN3_HVBPreheatPrecoolSta: start 63, 2 bit, big-endian, i-signal-type=PRIMITIVE, init-value=constant-reference=Init_CAN3_HVBPreheatPrecoolSta, base-type=uint8, implementation-data-type=uint8, transfer-property=TRIGGERED-ON-CHANGE
          signal CAN3_HVBSOCJumpError: start 78, 1 bit, big-endian, i-signal-type=PRIMITIVE, init-value=constant-reference=Init_CAN3_HVBSOCJumpError, base-type=uint8, implementation-data-type=uint8, transfer-property=TRIGGERED-ON-CHANGE
          signal CAN3_HVBShrtChrgCurrErr: start 86, 1 bit, big-endian, i-signal-type=PRIMITIVE, init-value=constant-reference=Init_CAN3_HVBShrtChrgCurrErr, base-type=uint8, implementation-data-type=uint8, transfer-property=TRIGGERED-ON-CHANGE
          signal CAN3_HVBShrtDischrgCurrErr: start 87, 1 bit, big-endian, i-signal-type=PRIMITIVE, init-value=constant-reference=Init_CAN3_HVBShrtDischrgCurrErr, base-type=uint8, implementation-data-type=uint8, transfer-property=TRIGGERED-ON-CHANGE
          signal CAN3_HVBTempDiffErr: start 70, 1 bit, big-endian, i-signal-type=PRIMITIVE, init-value=constant-reference=Init_CAN3_HVBTempDiffErr, base-type=uint8, implementation-data-type=uint8, transfer-property=TRIGGERED-ON-CHANGE
          signal CAN3_HVBUndrSOCErr: start 77, 1 bit, big-endian, i-signal-type=PRIMITIVE, init-value=constant-reference=Init_CAN3_HVBUndrSOCErr, base-type=uint8, implementation-data-type=uint8, transfer-property=TRIGGERED-ON-CHANGE
          signal CAN3_HVBUndrTempErr: start 75, 1 bit, big-endian, i-signal-type=PRIMITIVE, init-value=constant-reference=Init_CAN3_HVBUndrTempErr, base-type=uint8, implementation-data-type=uint8, transfer-property=TRIGGERED-ON-CHANGE
          signal CAN3_HVBUndrTempWarn: start 83, 2 bit, big-endian, i-signal-type=PRIMITIVE, init-value=constant-reference=Init_CAN3_HVBUndrTempWarn, base-type=uint8, implementation-data-type=uint8, transfer-property=TRIGGERED-ON-CHANGE
          signal CAN3_HVBUndrVoltErr: start 85, 1 bit, big-endian, i-signal-type=PRIMITIVE, init-value=constant-reference=Init_CAN3_HVBUndrVoltErr, base-type=uint8, implementation-data-type=uint8, transfer-property=TRIGGERED-ON-CHANGE
          signal CAN3_HVBattReady4Pre: start 57, 2 bit, big-endian, i-signal-type=PRIMITIVE, init-value=constant-reference=Init_CAN3_HVBattReady4Pre, base-type=uint8, implementation-data-type=uint8, transfer-property=TRIGGERED-ON-CHANGE
          signal CAN3_HVILSta: start 71, 1 bit, big-endian, i-signal-type=PRIMITIVE, init-value=constant-reference=Init_CAN3_HVILSta, base-type=uint8, implementation-data-type=uint8, transfer-property=TRIGGERED-ON-CHANGE
          signal CAN3_IsoDetSta: start 48, 1 bit, big-endian, i-signal-type=PRIMITIVE, init-value=constant-reference=Init_CAN3_IsoDetSta, base-type=uint8, implementation-data-type=uint8, transfer-property=TRIGGERED-ON-CHANGE
          signal CAN3_SystemUncomErr: start 49, 1 bit, big-endian, i-signal-type=PRIMITIVE, init-value=constant-reference=Init_CAN3_SystemUncomErr, base-type=uint8, implementation-data-type=uint8, transfer-property=TRIGGERED-ON-CHANGE
          signal CAN3_V2LSta: start 25, 2 bit, big-endian, i-signal-type=PRIMITIVE, init-value=constant-reference=Init_CAN3_V2LSta, base-type=uint8, implementation-data-type=uint8, transfer-property=TRIGGERED-ON-CHANGE
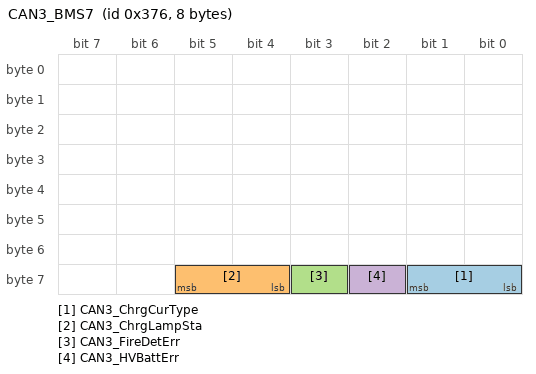
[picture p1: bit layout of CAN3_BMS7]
      frame CAN3_BMS7: id 0x376, frame-length=8, can-addressing-mode=STANDARD, can-fd-frame-support=true, can-frame-rx-behavior=CAN-FD, can-frame-tx-behavior=CAN-FD
        pdu CAN3_BMS7: length=8, minimum-delay=0.0, transmission-mode-true-timing={cyclic-timing=time-period=1, event-controlled-timing={number-of-repetitions=0, repetition-period=0.01}}, unused-bit-pattern=0
          mapping CAN3_SG_BMS7: i-signal-group=CAN3_SG_BMS7, start-position=0, transfer-property=TRIGGERED-ON-CHANGE
          signal CAN3_ChrgCurType: start 57, 2 bit, big-endian, i-signal-type=PRIMITIVE, init-value=constant-reference=Init_CAN3_ChrgCurType, base-type=uint8, implementation-data-type=uint8, transfer-property=TRIGGERED-ON-CHANGE
          signal CAN3_ChrgLampSta: start 61, 2 bit, big-endian, i-signal-type=PRIMITIVE, init-value=constant-reference=Init_CAN3_ChrgLampSta, base-type=uint8, implementation-data-type=uint8, transfer-property=TRIGGERED-ON-CHANGE
          signal CAN3_FireDetErr: start 59, 1 bit, big-endian, i-signal-type=PRIMITIVE, init-value=constant-reference=Init_CAN3_FireDetErr, base-type=uint8, implementation-data-type=uint8, transfer-property=TRIGGERED-ON-CHANGE
          signal CAN3_HVBattErr: start 58, 1 bit, big-endian, i-signal-type=PRIMITIVE, init-value=constant-reference=Init_CAN3_HVBattErr, base-type=uint8, implementation-data-type=uint8, transfer-property=TRIGGERED-ON-CHANGE
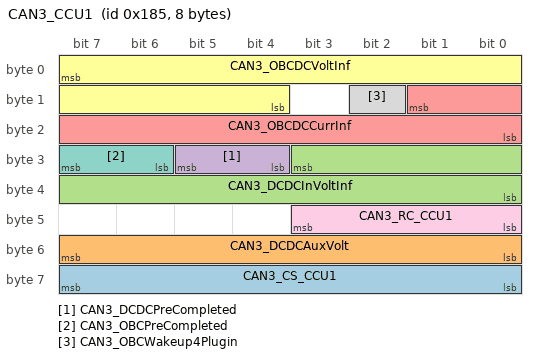
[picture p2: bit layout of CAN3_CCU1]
      frame CAN3_CCU1: id 0x185, frame-length=8, can-addressing-mode=STANDARD, can-fd-frame-support=true, can-frame-rx-behavior=CAN-FD, can-frame-tx-behavior=CAN-FD
        pdu CAN3_CCU1: length=8, minimum-delay=0.0, transmission-mode-true-timing=cyclic-timing=time-period=0.01, unused-bit-pattern=0
          mapping CAN3_SG_CCU1: i-signal-group=CAN3_SG_CCU1, start-position=0, transfer-property=PENDING
          signal CAN3_CS_CCU1: start 63, 8 bit, big-endian, i-signal-type=PRIMITIVE, init-value=constant-reference=Init_CAN3_CS_CCU1, base-type=uint8, implementation-data-type=uint8, transfer-property=PENDING
          signal CAN3_DCDCAuxVolt: start 55, 8 bit, big-endian, i-signal-type=PRIMITIVE, init-value=constant-reference=Init_CAN3_DCDCAuxVolt, base-type=uint8, implementation-data-type=uint8, transfer-property=PENDING
          signal CAN3_DCDCInVoltInf: start 27, 12 bit, big-endian, i-signal-type=PRIMITIVE, init-value=constant-reference=Init_CAN3_DCDCInVoltInf, base-type=uint16, implementation-data-type=uint16, transfer-property=PENDING
          signal CAN3_DCDCPreCompleted: start 29, 2 bit, big-endian, i-signal-type=PRIMITIVE, init-value=constant-reference=Init_CAN3_DCDCPreCompleted, base-type=uint8, implementation-data-type=uint8, transfer-property=PENDING
          signal CAN3_OBCDCCurrInf: start 9, 10 bit, big-endian, i-signal-type=PRIMITIVE, init-value=constant-reference=Init_CAN3_OBCDCCurrInf, base-type=uint16, implementation-data-type=uint16, transfer-property=PENDING
          signal CAN3_OBCDCVoltInf: start 7, 12 bit, big-endian, i-signal-type=PRIMITIVE, init-value=constant-reference=Init_CAN3_OBCDCVoltInf, base-type=uint16, implementation-data-type=uint16, transfer-property=PENDING
          signal CAN3_OBCPreCompleted: start 31, 2 bit, big-endian, i-signal-type=PRIMITIVE, init-value=constant-reference=Init_CAN3_OBCPreCompleted, base-type=uint8, implementation-data-type=uint8, transfer-property=PENDING
          signal CAN3_OBCWakeup4Plugin: start 10, 1 bit, big-endian, i-signal-type=PRIMITIVE, init-value=constant-reference=Init_CAN3_OBCWakeup4Plugin, base-type=uint8, implementation-data-type=uint8, transfer-property=PENDING
          signal CAN3_RC_CCU1: start 43, 4 bit, big-endian, i-signal-type=PRIMITIVE, init-value=constant-reference=Init_CAN3_RC_CCU1, base-type=uint8, implementation-data-type=uint8, transfer-property=PENDING
      frame CAN3_CCU2: id 0x1D6, frame-length=12, can-addressing-mode=STANDARD, can-fd-frame-support=true, can-frame-rx-behavior=CAN-FD, can-frame-tx-behavior=CAN-FD
        pdu CAN3_CCU2: length=12, minimum-delay=0.0, transmission-mode-true-timing={cyclic-timing=time-period=0.1, event-controlled-timing={number-of-repetitions=0, repetition-period=0.01}}, unused-bit-pattern=0
          mapping CAN3_SG_CCU2: i-signal-group=CAN3_SG_CCU2, start-position=0, transfer-property=TRIGGERED-ON-CHANGE
          signal CAN3_CS_CCU2: start 7, 8 bit, big-endian, i-signal-type=PRIMITIVE, init-value=constant-reference=Init_CAN3_CS_CCU2, base-type=uint8, implementation-data-type=uint8, transfer-property=PENDING
          signal CAN3_DCDCEnaSta: start 58, 1 bit, big-endian, i-signal-type=PRIMITIVE, init-value=constant-reference=Init_CAN3_DCDCEnaSta, base-type=uint8, implementation-data-type=uint8, transfer-property=TRIGGERED-ON-CHANGE
          signal CAN3_DCDCFaultSta: start 91, 2 bit, big-endian, i-signal-type=PRIMITIVE, init-value=constant-reference=Init_CAN3_DCDCFaultSta, base-type=uint8, implementation-data-type=uint8, transfer-property=TRIGGERED-ON-CHANGE
          signal CAN3_DCDCReady4Pre: start 93, 1 bit, big-endian, i-signal-type=PRIMITIVE, init-value=constant-reference=Init_CAN3_DCDCReady4Pre, base-type=uint8, implementation-data-type=uint8, transfer-property=TRIGGERED-ON-CHANGE
          signal CAN3_DCDCTemp: start 79, 8 bit, big-endian, i-signal-type=PRIMITIVE, init-value=constant-reference=Init_CAN3_DCDCTemp, base-type=uint8, implementation-data-type=uint8, transfer-property=TRIGGERED-ON-CHANGE
          signal CAN3_OBCACCurrInf: start 55, 10 bit, big-endian, i-signal-type=PRIMITIVE, init-value=constant-reference=Init_CAN3_OBCACCurrInf, base-type=uint16, implementation-data-type=uint16, transfer-property=PENDING
          signal CAN3_OBCACVoltInf: start 35, 12 bit, big-endian, i-signal-type=PRIMITIVE, init-value=constant-reference=Init_CAN3_OBCACVoltInf, base-type=uint16, implementation-data-type=uint16, transfer-property=PENDING
          signal CAN3_OBCDCP: start 57, 10 bit, big-endian, i-signal-type=PRIMITIVE, init-value=constant-reference=Init_CAN3_OBCDCP, base-type=uint16, implementation-data-type=uint16, transfer-property=PENDING
          signal CAN3_OBCEnaSta: start 60, 1 bit, big-endian, i-signal-type=PRIMITIVE, init-value=constant-reference=Init_CAN3_OBCEnaSta, base-type=uint8, implementation-data-type=uint8, transfer-property=TRIGGERED-ON-CHANGE
          signal CAN3_OBCFaultSta: start 89, 2 bit, big-endian, i-signal-type=PRIMITIVE, init-value=constant-reference=Init_CAN3_OBCFaultSta, base-type=uint8, implementation-data-type=uint8, transfer-property=TRIGGERED-ON-CHANGE
          signal CAN3_OBCPluginSta: start 59, 1 bit, big-endian, i-signal-type=PRIMITIVE, init-value=constant-reference=Init_CAN3_OBCPluginSta, base-type=uint8, implementation-data-type=uint8, transfer-property=PENDING
          signal CAN3_OBCReady4Pre: start 92, 1 bit, big-endian, i-signal-type=PRIMITIVE, init-value=constant-reference=Init_CAN3_OBCReady4Pre, base-type=uint8, implementation-data-type=uint8, transfer-property=TRIGGERED-ON-CHANGE
          signal CAN3_OBCTemp: start 87, 9 bit, big-endian, i-signal-type=PRIMITIVE, init-value=constant-reference=Init_CAN3_OBCTemp, base-type=uint16, implementation-data-type=uint16, transfer-property=PENDING
          signal CAN3_OBCV2LSta: start 9, 2 bit, big-endian, i-signal-type=PRIMITIVE, init-value=constant-reference=Init_CAN3_OBCV2LSta, base-type=uint8, implementation-data-type=uint8, transfer-property=TRIGGERED-ON-CHANGE
          signal CAN3_OBC_AC_Cur_Lim: start 37, 2 bit, big-endian, i-signal-type=PRIMITIVE, init-value=constant-reference=Init_CAN3_OBC_AC_Cur_Lim, base-type=uint8, implementation-data-type=uint8, transfer-property=TRIGGERED-ON-CHANGE
          signal CAN3_RC_CCU2: start 15, 4 bit, big-endian, i-signal-type=PRIMITIVE, init-value=constant-reference=Init_CAN3_RC_CCU2, base-type=uint8, implementation-data-type=uint8, transfer-property=PENDING
          signal CAN3_ReqOBCV2LEna: start 11, 2 bit, big-endian, i-signal-type=PRIMITIVE, init-value=constant-reference=Init_CAN3_ReqOBCV2LEna, base-type=uint8, implementation-data-type=uint8, transfer-property=TRIGGERED-ON-CHANGE
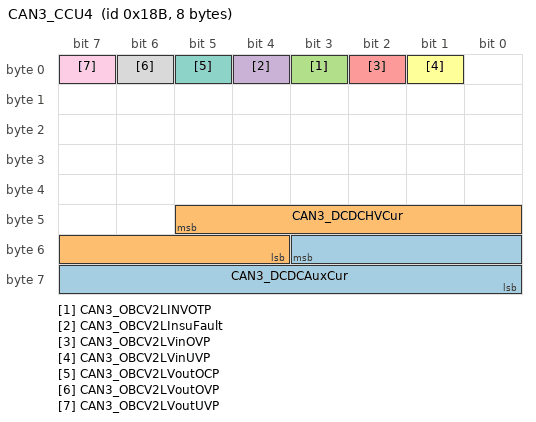
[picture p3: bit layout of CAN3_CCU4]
      frame CAN3_CCU4: id 0x18B, frame-length=8, can-addressing-mode=STANDARD, can-fd-frame-support=true, can-frame-rx-behavior=CAN-FD, can-frame-tx-behavior=CAN-FD
        pdu CAN3_CCU4: length=8, minimum-delay=0.0, transmission-mode-true-timing={cyclic-timing=time-period=0.01, event-controlled-timing={number-of-repetitions=0, repetition-period=0.01}}, unused-bit-pattern=0
          mapping CAN3_SG_CCU4: i-signal-group=CAN3_SG_CCU4, start-position=0, transfer-property=TRIGGERED-ON-CHANGE
          signal CAN3_DCDCAuxCur: start 51, 12 bit, big-endian, i-signal-type=PRIMITIVE, init-value=constant-reference=Init_CAN3_DCDCAuxCur, base-type=uint16, implementation-data-type=uint16, transfer-property=PENDING
          signal CAN3_DCDCHVCur: start 45, 10 bit, big-endian, i-signal-type=PRIMITIVE, init-value=constant-reference=Init_CAN3_DCDCHVCur, base-type=uint16, implementation-data-type=uint16, transfer-property=PENDING
          signal CAN3_OBCV2LINVOTP: start 3, 1 bit, big-endian, i-signal-type=PRIMITIVE, init-value=constant-reference=Init_CAN3_OBCV2LINVOTP, base-type=uint8, implementation-data-type=uint8, transfer-property=TRIGGERED-ON-CHANGE
          signal CAN3_OBCV2LInsuFault: start 4, 1 bit, big-endian, i-signal-type=PRIMITIVE, init-value=constant-reference=Init_CAN3_OBCV2LInsuFault, base-type=uint8, implementation-data-type=uint8, transfer-property=TRIGGERED-ON-CHANGE
          signal CAN3_OBCV2LVinOVP: start 2, 1 bit, big-endian, i-signal-type=PRIMITIVE, init-value=constant-reference=Init_CAN3_OBCV2LVinOVP, base-type=uint8, implementation-data-type=uint8, transfer-property=PENDING
          signal CAN3_OBCV2LVinUVP: start 1, 1 bit, big-endian, i-signal-type=PRIMITIVE, init-value=constant-reference=Init_CAN3_OBCV2LVinUVP, base-type=uint8, implementation-data-type=uint8, transfer-property=PENDING
          signal CAN3_OBCV2LVoutOCP: start 5, 1 bit, big-endian, i-signal-type=PRIMITIVE, init-value=constant-reference=Init_CAN3_OBCV2LVoutOCP, base-type=uint8, implementation-data-type=uint8, transfer-property=TRIGGERED-ON-CHANGE
          signal CAN3_OBCV2LVoutOVP: start 6, 1 bit, big-endian, i-signal-type=PRIMITIVE, init-value=constant-reference=Init_CAN3_OBCV2LVoutOVP, base-type=uint8, implementation-data-type=uint8, transfer-property=TRIGGERED-ON-CHANGE
          signal CAN3_OBCV2LVoutUVP: start 7, 1 bit, big-endian, i-signal-type=PRIMITIVE, init-value=constant-reference=Init_CAN3_OBCV2LVoutUVP, base-type=uint8, implementation-data-type=uint8, transfer-property=TRIGGERED-ON-CHANGE
      frame CAN3_DiagFuncReqFT: id 0x7D0, frame-length=8, can-addressing-mode=STANDARD, can-fd-frame-support=true, can-frame-rx-behavior=CAN-FD, can-frame-tx-behavior=CAN-FD
        n pdu CAN3_DiagFuncReqFT: length=8
      frame CAN3_DiagPhysReqToBMS: id 0x6B0, frame-length=8, can-addressing-mode=STANDARD, can-fd-frame-support=true, can-frame-rx-behavior=CAN-FD, can-frame-tx-behavior=CAN-FD
        n pdu CAN3_DiagPhysReqToBMS: length=8
      frame CAN3_DiagPhysReqToCCU: id 0x6B3, frame-length=8, can-addressing-mode=STANDARD, can-fd-frame-support=true, can-frame-rx-behavior=CAN-FD, can-frame-tx-behavior=CAN-FD
        n pdu CAN3_DiagPhysReqToCCU: length=8
      frame CAN3_DiagPhysReqToEOP_F: id 0x698, frame-length=8, can-addressing-mode=STANDARD, can-fd-frame-support=true, can-frame-rx-behavior=CAN-FD, can-frame-tx-behavior=CAN-FD
        n pdu CAN3_DiagPhysReqToEOP_F: length=8
      frame CAN3_DiagPhysReqToEOP_R: id 0x693, frame-length=8, can-addressing-mode=STANDARD, can-fd-frame-support=true, can-frame-rx-behavior=CAN-FD, can-frame-tx-behavior=CAN-FD
        n pdu CAN3_DiagPhysReqToEOP_R: length=8
      frame CAN3_DiagPhysReqToMCU_F: id 0x688, frame-length=8, can-addressing-mode=STANDARD, can-fd-frame-support=true, can-frame-rx-behavior=CAN-FD, can-frame-tx-behavior=CAN-FD
        n pdu CAN3_DiagPhysReqToMCU_F: length=8
      frame CAN3_DiagPhysReqToMCU_R: id 0x683, frame-length=8, can-addressing-mode=STANDARD, can-fd-frame-support=true, can-frame-rx-behavior=CAN-FD, can-frame-tx-behavior=CAN-FD
        n pdu CAN3_DiagPhysReqToMCU_R: length=8
      frame CAN3_DiagPhysReqToShifter: id 0x6B8, frame-length=8, can-addressing-mode=STANDARD, can-fd-frame-support=true, can-frame-rx-behavior=CAN-FD, can-frame-tx-behavior=CAN-FD
        n pdu CAN3_DiagPhysReqToShifter: length=8
      frame CAN3_DiagRespFromBMS: id 0x630, frame-length=8, can-addressing-mode=STANDARD, can-fd-frame-support=true, can-frame-rx-behavior=CAN-FD, can-frame-tx-behavior=CAN-FD
        n pdu CAN3_DiagRespFromBMS: length=8
      frame CAN3_DiagRespFromCCU: id 0x633, frame-length=8, can-addressing-mode=STANDARD, can-fd-frame-support=true, can-frame-rx-behavior=CAN-FD, can-frame-tx-behavior=CAN-FD
        n pdu CAN3_DiagRespFromCCU: length=8
      frame CAN3_DiagRespFromEOP_F: id 0x618, frame-length=8, can-addressing-mode=STANDARD, can-fd-frame-support=true, can-frame-rx-behavior=CAN-FD, can-frame-tx-behavior=CAN-FD
        n pdu CAN3_DiagRespFromEOP_F: length=8
      frame CAN3_DiagRespFromEOP_R: id 0x613, frame-length=8, can-addressing-mode=STANDARD, can-fd-frame-support=true, can-frame-rx-behavior=CAN-FD, can-frame-tx-behavior=CAN-FD
        n pdu CAN3_DiagRespFromEOP_R: length=8
      frame CAN3_DiagRespFromMCU_F: id 0x608, frame-length=8, can-addressing-mode=STANDARD, can-fd-frame-support=true, can-frame-rx-behavior=CAN-FD, can-frame-tx-behavior=CAN-FD
        n pdu CAN3_DiagRespFromMCU_F: length=8
      frame CAN3_DiagRespFromMCU_R: id 0x603, frame-length=8, can-addressing-mode=STANDARD, can-fd-frame-support=true, can-frame-rx-behavior=CAN-FD, can-frame-tx-behavior=CAN-FD
        n pdu CAN3_DiagRespFromMCU_R: length=8
      frame CAN3_DiagRespFromShifter: id 0x638, frame-length=8, can-addressing-mode=STANDARD, can-fd-frame-support=true, can-frame-rx-behavior=CAN-FD, can-frame-tx-behavior=CAN-FD
        n pdu CAN3_DiagRespFromShifter: length=8
      frame CAN3_FD_BCM1: id 0x216, frame-length=16, can-addressing-mode=STANDARD, can-fd-frame-support=true, can-frame-rx-behavior=CAN-FD, can-frame-tx-behavior=CAN-FD
        pdu CAN3_FD_BCM1: length=16, minimum-delay=0.0, transmission-mode-true-timing={cyclic-timing=time-period=0.2, event-controlled-timing={number-of-repetitions=0, repetition-period=0.06}}, unused-bit-pattern=0
          mapping CAN3_SG_FD_BCM1: i-signal-group=CAN3_SG_FD_BCM1, start-position=0, transfer-property=TRIGGERED-ON-CHANGE
          signal CAN3_AllDoorSW: start 124, 1 bit, big-endian, i-signal-type=PRIMITIVE, init-value=constant-reference=Init_CAN3_AllDoorSW, base-type=uint8, implementation-data-type=uint8, transfer-property=TRIGGERED-ON-CHANGE
          signal CAN3_AntiTheftSeatFold: start 84, 1 bit, big-endian, i-signal-type=PRIMITIVE, init-value=constant-reference=Init_CAN3_AntiTheftSeatFold, base-type=uint8, implementation-data-type=uint8, transfer-property=TRIGGERED-ON-CHANGE
          signal CAN3_AntitheftSta: start 83, 2 bit, big-endian, i-signal-type=PRIMITIVE, init-value=constant-reference=Init_CAN3_AntitheftSta, base-type=uint8, implementation-data-type=uint8, transfer-property=TRIGGERED-ON-CHANGE
          signal CAN3_BCM_Buzzer_Req: start 64, 1 bit, big-endian, i-signal-type=PRIMITIVE, init-value=constant-reference=Init_CAN3_BCM_Buzzer_Req, base-type=uint8, implementation-data-type=uint8, transfer-property=TRIGGERED-ON-CHANGE
          signal CAN3_BCM_DoorLock_Sta: start 70, 1 bit, big-endian, i-signal-type=PRIMITIVE, init-value=constant-reference=Init_CAN3_BCM_DoorLock_Sta, base-type=uint8, implementation-data-type=uint8, transfer-property=TRIGGERED-ON-CHANGE
          signal CAN3_BrakeLamp: start 90, 1 bit, big-endian, i-signal-type=PRIMITIVE, init-value=constant-reference=Init_CAN3_BrakeLamp, base-type=uint8, implementation-data-type=uint8, transfer-property=TRIGGERED-ON-CHANGE
          signal CAN3_CTDCtrl: start 113, 2 bit, big-endian, i-signal-type=PRIMITIVE, init-value=constant-reference=Init_CAN3_CTDCtrl, base-type=uint8, implementation-data-type=uint8, transfer-property=TRIGGERED-ON-CHANGE
          signal CAN3_CTDLockSW: start 118, 1 bit, big-endian, i-signal-type=PRIMITIVE, init-value=constant-reference=Init_CAN3_CTDLockSW, base-type=uint8, implementation-data-type=uint8, transfer-property=TRIGGERED-ON-CHANGE
          signal CAN3_CTDUnlockSW: start 119, 1 bit, big-endian, i-signal-type=PRIMITIVE, init-value=constant-reference=Init_CAN3_CTDUnlockSW, base-type=uint8, implementation-data-type=uint8, transfer-property=TRIGGERED-ON-CHANGE
          signal CAN3_CrashDetd: start 85, 1 bit, big-endian, i-signal-type=PRIMITIVE, init-value=constant-reference=Init_CAN3_CrashDetd, base-type=uint8, implementation-data-type=uint8, transfer-property=TRIGGERED-ON-CHANGE
          signal CAN3_Dimmer: start 78, 7 bit, big-endian, i-signal-type=PRIMITIVE, init-value=constant-reference=Init_CAN3_Dimmer, base-type=uint8, implementation-data-type=uint8, transfer-property=TRIGGERED-ON-CHANGE
          signal CAN3_DimmerEN: start 69, 1 bit, big-endian, i-signal-type=PRIMITIVE, init-value=constant-reference=Init_CAN3_DimmerEN, base-type=uint8, implementation-data-type=uint8, transfer-property=TRIGGERED-ON-CHANGE
          signal CAN3_DoorLockIND: start 125, 1 bit, big-endian, i-signal-type=PRIMITIVE, init-value=constant-reference=Init_CAN3_DoorLockIND, base-type=uint8, implementation-data-type=uint8, transfer-property=TRIGGERED-ON-CHANGE
          signal CAN3_DrDoorSW: start 120, 1 bit, big-endian, i-signal-type=PRIMITIVE, init-value=constant-reference=Init_CAN3_DrDoorSW, base-type=uint8, implementation-data-type=uint8, transfer-property=TRIGGERED-ON-CHANGE
          signal CAN3_Fr_ChargingDoorCtrl: start 115, 2 bit, big-endian, i-signal-type=PRIMITIVE, init-value=constant-reference=Init_CAN3_Fr_ChargingDoorCtrl, base-type=uint8, implementation-data-type=uint8, transfer-property=TRIGGERED-ON-CHANGE
          signal CAN3_Fr_FogLamp: start 93, 1 bit, big-endian, i-signal-type=PRIMITIVE, init-value=constant-reference=Init_CAN3_Fr_FogLamp, base-type=uint8, implementation-data-type=uint8, transfer-property=TRIGGERED-ON-CHANGE
          signal CAN3_Fr_Wiper_H: start 110, 1 bit, big-endian, i-signal-type=PRIMITIVE, init-value=constant-reference=Init_CAN3_Fr_Wiper_H, base-type=uint8, implementation-data-type=uint8, transfer-property=TRIGGERED-ON-CHANGE
          signal CAN3_Fr_Wiper_L: start 111, 1 bit, big-endian, i-signal-type=PRIMITIVE, init-value=constant-reference=Init_CAN3_Fr_Wiper_L, base-type=uint8, implementation-data-type=uint8, transfer-property=TRIGGERED-ON-CHANGE
          signal CAN3_H_Beam: start 101, 1 bit, big-endian, i-signal-type=PRIMITIVE, init-value=constant-reference=Init_CAN3_H_Beam, base-type=uint8, implementation-data-type=uint8, transfer-property=TRIGGERED-ON-CHANGE
          signal CAN3_HazardSW: start 95, 1 bit, big-endian, i-signal-type=PRIMITIVE, init-value=constant-reference=Init_CAN3_HazardSW, base-type=uint8, implementation-data-type=uint8, transfer-property=TRIGGERED-ON-CHANGE
          signal CAN3_HoodSW: start 126, 1 bit, big-endian, i-signal-type=PRIMITIVE, init-value=constant-reference=Init_CAN3_HoodSW, base-type=uint8, implementation-data-type=uint8, transfer-property=TRIGGERED-ON-CHANGE
          signal CAN3_HornCtrl: start 71, 1 bit, big-endian, i-signal-type=PRIMITIVE, init-value=constant-reference=Init_CAN3_HornCtrl, base-type=uint8, implementation-data-type=uint8, transfer-property=TRIGGERED-ON-CHANGE
          signal CAN3_LBSD: start 91, 1 bit, big-endian, i-signal-type=PRIMITIVE, init-value=constant-reference=Init_CAN3_LBSD, base-type=uint8, implementation-data-type=uint8, transfer-property=TRIGGERED-ON-CHANGE
          signal CAN3_LDRL: start 103, 1 bit, big-endian, i-signal-type=PRIMITIVE, init-value=constant-reference=Init_CAN3_LDRL, base-type=uint8, implementation-data-type=uint8, transfer-property=TRIGGERED-ON-CHANGE
          signal CAN3_LTurnLP: start 80, 1 bit, big-endian, i-signal-type=PRIMITIVE, init-value=constant-reference=Init_CAN3_LTurnLP, base-type=uint8, implementation-data-type=uint8, transfer-property=TRIGGERED-ON-CHANGE
          signal CAN3_L_APM_WdwEnable: start 87, 1 bit, big-endian, i-signal-type=PRIMITIVE, init-value=constant-reference=Init_CAN3_L_APM_WdwEnable, base-type=uint8, implementation-data-type=uint8, transfer-property=TRIGGERED-ON-CHANGE
          signal CAN3_L_Beam: start 100, 1 bit, big-endian, i-signal-type=PRIMITIVE, init-value=constant-reference=Init_CAN3_L_Beam, base-type=uint8, implementation-data-type=uint8, transfer-property=TRIGGERED-ON-CHANGE
          signal CAN3_LockSetting: start 79, 1 bit, big-endian, i-signal-type=PRIMITIVE, init-value=constant-reference=Init_CAN3_LockSetting, base-type=uint8, implementation-data-type=uint8, transfer-property=TRIGGERED-ON-CHANGE
          signal CAN3_MirrorCtrl: start 109, 2 bit, big-endian, i-signal-type=PRIMITIVE, init-value=constant-reference=Init_CAN3_MirrorCtrl, base-type=uint8, implementation-data-type=uint8, transfer-property=TRIGGERED-ON-CHANGE
          signal CAN3_MirrorDefog: start 104, 1 bit, big-endian, i-signal-type=PRIMITIVE, init-value=constant-reference=Init_CAN3_MirrorDefog, base-type=uint8, implementation-data-type=uint8, transfer-property=TRIGGERED-ON-CHANGE
          signal CAN3_PmicBootReason: start 39, 8 bit, big-endian, i-signal-type=PRIMITIVE, init-value=constant-reference=Init_CAN3_PmicBootReason, base-type=uint8, implementation-data-type=uint8, transfer-property=PENDING
          signal CAN3_PosLamp: start 102, 1 bit, big-endian, i-signal-type=PRIMITIVE, init-value=constant-reference=Init_CAN3_PosLamp, base-type=uint8, implementation-data-type=uint8, transfer-property=TRIGGERED-ON-CHANGE
          signal CAN3_PsDoorSW: start 121, 1 bit, big-endian, i-signal-type=PRIMITIVE, init-value=constant-reference=Init_CAN3_PsDoorSW, base-type=uint8, implementation-data-type=uint8, transfer-property=TRIGGERED-ON-CHANGE
          signal CAN3_RBSD: start 92, 1 bit, big-endian, i-signal-type=PRIMITIVE, init-value=constant-reference=Init_CAN3_RBSD, base-type=uint8, implementation-data-type=uint8, transfer-property=TRIGGERED-ON-CHANGE
          signal CAN3_RDRL: start 88, 1 bit, big-endian, i-signal-type=PRIMITIVE, init-value=constant-reference=Init_CAN3_RDRL, base-type=uint8, implementation-data-type=uint8, transfer-property=TRIGGERED-ON-CHANGE
          signal CAN3_RLDoorSW: start 122, 1 bit, big-endian, i-signal-type=PRIMITIVE, init-value=constant-reference=Init_CAN3_RLDoorSW, base-type=uint8, implementation-data-type=uint8, transfer-property=TRIGGERED-ON-CHANGE
          signal CAN3_RRDoorSW: start 123, 1 bit, big-endian, i-signal-type=PRIMITIVE, init-value=constant-reference=Init_CAN3_RRDoorSW, base-type=uint8, implementation-data-type=uint8, transfer-property=TRIGGERED-ON-CHANGE
          signal CAN3_RTurnLP: start 81, 1 bit, big-endian, i-signal-type=PRIMITIVE, init-value=constant-reference=Init_CAN3_RTurnLP, base-type=uint8, implementation-data-type=uint8, transfer-property=TRIGGERED-ON-CHANGE
          signal CAN3_ReverseLamp: start 89, 1 bit, big-endian, i-signal-type=PRIMITIVE, init-value=constant-reference=Init_CAN3_ReverseLamp, base-type=uint8, implementation-data-type=uint8, transfer-property=TRIGGERED-ON-CHANGE
          signal CAN3_RoomLampH: start 68, 1 bit, big-endian, i-signal-type=PRIMITIVE, init-value=constant-reference=Init_CAN3_RoomLampH, base-type=uint8, implementation-data-type=uint8, transfer-property=TRIGGERED-ON-CHANGE
          signal CAN3_RoomLampL: start 67, 1 bit, big-endian, i-signal-type=PRIMITIVE, init-value=constant-reference=Init_CAN3_RoomLampL, base-type=uint8, implementation-data-type=uint8, transfer-property=TRIGGERED-ON-CHANGE
          signal CAN3_Rr_ChargingDoorCtrl: start 117, 2 bit, big-endian, i-signal-type=PRIMITIVE, init-value=constant-reference=Init_CAN3_Rr_ChargingDoorCtrl, base-type=uint8, implementation-data-type=uint8, transfer-property=TRIGGERED-ON-CHANGE
          signal CAN3_Rr_Defog: start 105, 1 bit, big-endian, i-signal-type=PRIMITIVE, init-value=constant-reference=Init_CAN3_Rr_Defog, base-type=uint8, implementation-data-type=uint8, transfer-property=TRIGGERED-ON-CHANGE
          signal CAN3_Rr_FogLamp: start 94, 1 bit, big-endian, i-signal-type=PRIMITIVE, init-value=constant-reference=Init_CAN3_Rr_FogLamp, base-type=uint8, implementation-data-type=uint8, transfer-property=TRIGGERED-ON-CHANGE
          signal CAN3_Rr_Wiper: start 96, 1 bit, big-endian, i-signal-type=PRIMITIVE, init-value=constant-reference=Init_CAN3_Rr_Wiper, base-type=uint8, implementation-data-type=uint8, transfer-property=TRIGGERED-ON-CHANGE
          signal CAN3_TailgateHDSW: start 107, 1 bit, big-endian, i-signal-type=PRIMITIVE, init-value=constant-reference=Init_CAN3_TailgateHDSW, base-type=uint8, implementation-data-type=uint8, transfer-property=TRIGGERED-ON-CHANGE
          signal CAN3_TailgateRemote: start 66, 2 bit, big-endian, i-signal-type=PRIMITIVE, init-value=constant-reference=Init_CAN3_TailgateRemote, base-type=uint8, implementation-data-type=uint8, transfer-property=TRIGGERED-ON-CHANGE
          signal CAN3_Tailgate_SW: start 127, 1 bit, big-endian, i-signal-type=PRIMITIVE, init-value=constant-reference=Init_CAN3_Tailgate_SW, base-type=uint8, implementation-data-type=uint8, transfer-property=TRIGGERED-ON-CHANGE
          signal CAN3_TrunkRel: start 106, 1 bit, big-endian, i-signal-type=PRIMITIVE, init-value=constant-reference=Init_CAN3_TrunkRel, base-type=uint8, implementation-data-type=uint8, transfer-property=TRIGGERED-ON-CHANGE
          signal CAN3_WasherCtrl: start 99, 2 bit, big-endian, i-signal-type=PRIMITIVE, init-value=constant-reference=Init_CAN3_WasherCtrl, base-type=uint8, implementation-data-type=uint8, transfer-property=TRIGGERED-ON-CHANGE
          signal CAN3_WiperFixMode: start 97, 1 bit, big-endian, i-signal-type=PRIMITIVE, init-value=constant-reference=Init_CAN3_WiperFixMode, base-type=uint8, implementation-data-type=uint8, transfer-property=TRIGGERED-ON-CHANGE
          signal CAN3_WisrBootReason: start 7, 32 bit, big-endian, i-signal-type=PRIMITIVE, init-value=constant-reference=Init_CAN3_WisrBootReason, base-type=uint32, implementation-data-type=uint32, transfer-property=PENDING
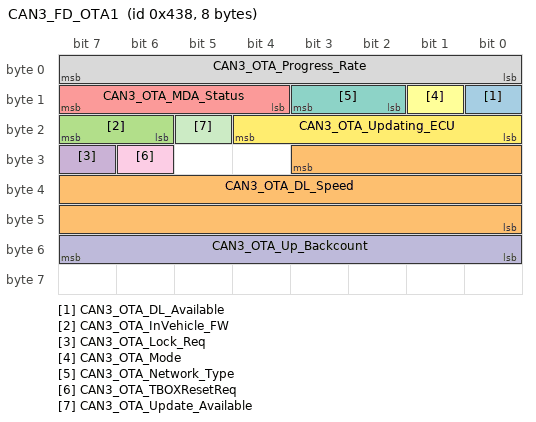
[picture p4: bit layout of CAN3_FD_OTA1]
      frame CAN3_FD_OTA1: id 0x438, frame-length=8, can-addressing-mode=STANDARD, can-fd-frame-support=true, can-frame-rx-behavior=CAN-FD, can-frame-tx-behavior=CAN-FD
        pdu CAN3_FD_OTA1: length=8, minimum-delay=0.0, transmission-mode-true-timing={cyclic-timing=time-period=0.2, event-controlled-timing={number-of-repetitions=0, repetition-period=0.02}}, unused-bit-pattern=0
          mapping CAN3_SG_FD_OTA1: i-signal-group=CAN3_SG_FD_OTA1, start-position=0, transfer-property=TRIGGERED-ON-CHANGE
          signal CAN3_OTA_DL_Available: start 8, 1 bit, big-endian, i-signal-type=PRIMITIVE, init-value=constant-reference=Init_CAN3_OTA_DL_Available, base-type=uint8, implementation-data-type=uint8, transfer-property=TRIGGERED-ON-CHANGE
          signal CAN3_OTA_DL_Speed: start 27, 20 bit, big-endian, i-signal-type=PRIMITIVE, init-value=constant-reference=Init_CAN3_OTA_DL_Speed, base-type=uint32, implementation-data-type=uint32, transfer-property=TRIGGERED-ON-CHANGE
          signal CAN3_OTA_InVehicle_FW: start 23, 2 bit, big-endian, i-signal-type=PRIMITIVE, init-value=constant-reference=Init_CAN3_OTA_InVehicle_FW, base-type=uint8, implementation-data-type=uint8, transfer-property=TRIGGERED-ON-CHANGE
          signal CAN3_OTA_Lock_Req: start 31, 1 bit, big-endian, i-signal-type=PRIMITIVE, init-value=constant-reference=Init_CAN3_OTA_Lock_Req, base-type=uint8, implementation-data-type=uint8, transfer-property=TRIGGERED-ON-CHANGE
          signal CAN3_OTA_MDA_Status: start 15, 4 bit, big-endian, i-signal-type=PRIMITIVE, init-value=constant-reference=Init_CAN3_OTA_MDA_Status, base-type=uint8, implementation-data-type=uint8, transfer-property=TRIGGERED-ON-CHANGE
          signal CAN3_OTA_Mode: start 9, 1 bit, big-endian, i-signal-type=PRIMITIVE, init-value=constant-reference=Init_CAN3_OTA_Mode, base-type=uint8, implementation-data-type=uint8, transfer-property=TRIGGERED-ON-CHANGE
          signal CAN3_OTA_Network_Type: start 11, 2 bit, big-endian, i-signal-type=PRIMITIVE, init-value=constant-reference=Init_CAN3_OTA_Network_Type, base-type=uint8, implementation-data-type=uint8, transfer-property=TRIGGERED-ON-CHANGE
          signal CAN3_OTA_Progress_Rate: start 7, 8 bit, big-endian, i-signal-type=PRIMITIVE, init-value=constant-reference=Init_CAN3_OTA_Progress_Rate, base-type=uint8, implementation-data-type=uint8, transfer-property=TRIGGERED-ON-CHANGE
          signal CAN3_OTA_TBOXResetReq: start 30, 1 bit, big-endian, i-signal-type=PRIMITIVE, init-value=constant-reference=Init_CAN3_OTA_TBOXResetReq, base-type=uint8, implementation-data-type=uint8, transfer-property=PENDING
          signal CAN3_OTA_Up_Backcount: start 55, 8 bit, big-endian, i-signal-type=PRIMITIVE, init-value=constant-reference=Init_CAN3_OTA_Up_Backcount, base-type=uint8, implementation-data-type=uint8, transfer-property=TRIGGERED-ON-CHANGE
          signal CAN3_OTA_Update_Available: start 21, 1 bit, big-endian, i-signal-type=PRIMITIVE, init-value=constant-reference=Init_CAN3_OTA_Update_Available, base-type=uint8, implementation-data-type=uint8, transfer-property=TRIGGERED-ON-CHANGE
          signal CAN3_OTA_Updating_ECU: start 20, 5 bit, big-endian, i-signal-type=PRIMITIVE, init-value=constant-reference=Init_CAN3_OTA_Updating_ECU, base-type=uint8, implementation-data-type=uint8, transfer-property=TRIGGERED-ON-CHANGE
      frame CAN3_FD_THCM1: id 0x182, frame-length=20, can-addressing-mode=STANDARD, can-fd-frame-support=true, can-frame-rx-behavior=CAN-FD, can-frame-tx-behavior=CAN-FD
        pdu CAN3_FD_THCM1: length=20, minimum-delay=0.0, transmission-mode-true-timing=cyclic-timing=time-period=0.1, unused-bit-pattern=0
          mapping CAN3_SG_FD_THCM1: i-signal-group=CAN3_SG_FD_THCM1, start-position=0, transfer-property=PENDING
          signal CAN3_BatteryMode: start 118, 3 bit, big-endian, i-signal-type=PRIMITIVE, init-value=constant-reference=Init_CAN3_BatteryMode, base-type=uint8, implementation-data-type=uint8, transfer-property=PENDING
          signal CAN3_CCU_ACLampSts: start 6, 1 bit, big-endian, i-signal-type=PRIMITIVE, init-value=constant-reference=Init_CAN3_CCU_ACLampSts, base-type=uint8, implementation-data-type=uint8, transfer-property=PENDING
          signal CAN3_CCU_ACMaxLampSts: start 1, 1 bit, big-endian, i-signal-type=PRIMITIVE, init-value=constant-reference=Init_CAN3_CCU_ACMaxLampSts, base-type=uint8, implementation-data-type=uint8, transfer-property=PENDING
          signal CAN3_CCU_AutoLampSts: start 2, 1 bit, big-endian, i-signal-type=PRIMITIVE, init-value=constant-reference=Init_CAN3_CCU_AutoLampSts, base-type=uint8, implementation-data-type=uint8, transfer-property=PENDING
          signal CAN3_CCU_AutoMidLampSts: start 3, 1 bit, big-endian, i-signal-type=PRIMITIVE, init-value=constant-reference=Init_CAN3_CCU_AutoMidLampSts, base-type=uint8, implementation-data-type=uint8, transfer-property=PENDING
          signal CAN3_CCU_Dispaly_Request: start 5, 1 bit, big-endian, i-signal-type=PRIMITIVE, init-value=constant-reference=Init_CAN3_CCU_Dispaly_Request, base-type=uint8, implementation-data-type=uint8, transfer-property=PENDING
          signal CAN3_CCU_EcoSts: start 4, 1 bit, big-endian, i-signal-type=PRIMITIVE, init-value=constant-reference=Init_CAN3_CCU_EcoSts, base-type=uint8, implementation-data-type=uint8, transfer-property=PENDING
          signal CAN3_CCU_FrtOnOffLampSts: start 19, 1 bit, big-endian, i-signal-type=PRIMITIVE, init-value=constant-reference=Init_CAN3_CCU_FrtOnOffLampSts, base-type=uint8, implementation-data-type=uint8, transfer-property=PENDING
          signal CAN3_CCU_HEATMaxLampSts: start 7, 1 bit, big-endian, i-signal-type=PRIMITIVE, init-value=constant-reference=Init_CAN3_CCU_HEATMaxLampSts, base-type=uint8, implementation-data-type=uint8, transfer-property=PENDING
          signal CAN3_CCU_RrOnOffLampSts: start 23, 1 bit, big-endian, i-signal-type=PRIMITIVE, init-value=constant-reference=Init_CAN3_CCU_RrOnOffLampSts, base-type=uint8, implementation-data-type=uint8, transfer-property=PENDING
          signal CAN3_CCU_SyncLampSts: start 39, 1 bit, big-endian, i-signal-type=PRIMITIVE, init-value=constant-reference=Init_CAN3_CCU_SyncLampSts, base-type=uint8, implementation-data-type=uint8, transfer-property=PENDING
          signal CAN3_CabinMode: start 115, 4 bit, big-endian, i-signal-type=PRIMITIVE, init-value=constant-reference=Init_CAN3_CabinMode, base-type=uint8, implementation-data-type=uint8, transfer-property=PENDING
          signal CAN3_EDriveMode: start 63, 2 bit, big-endian, i-signal-type=PRIMITIVE, init-value=constant-reference=Init_CAN3_EDriveMode, base-type=uint8, implementation-data-type=uint8, transfer-property=PENDING
          signal CAN3_FD_AGS_Cmd: start 143, 8 bit, big-endian, i-signal-type=PRIMITIVE, init-value=constant-reference=Init_CAN3_FD_AGS_Cmd, base-type=uint8, implementation-data-type=uint8, transfer-property=PENDING
          signal CAN3_FD_RecyAuto_Cmd: start 111, 3 bit, big-endian, i-signal-type=PRIMITIVE, init-value=constant-reference=Init_CAN3_FD_RecyAuto_Cmd, base-type=uint8, implementation-data-type=uint8, transfer-property=PENDING
          signal CAN3_Fr_Coolantflow: start 61, 6 bit, big-endian, i-signal-type=PRIMITIVE, init-value=constant-reference=Init_CAN3_Fr_Coolantflow, base-type=uint8, implementation-data-type=uint8, transfer-property=PENDING
          signal CAN3_Fr_Coolanttemp: start 0, 9 bit, big-endian, i-signal-type=PRIMITIVE, init-value=constant-reference=Init_CAN3_Fr_Coolanttemp, base-type=uint16, implementation-data-type=uint16, transfer-property=PENDING
          signal CAN3_HPThermalRecoveryReq: start 55, 2 bit, big-endian, i-signal-type=PRIMITIVE, init-value=constant-reference=Init_CAN3_HPThermalRecoveryReq, base-type=uint8, implementation-data-type=uint8, transfer-property=PENDING
          signal CAN3_Rr_Coolantflow: start 150, 6 bit, big-endian, i-signal-type=PRIMITIVE, init-value=constant-reference=Init_CAN3_Rr_Coolantflow, base-type=uint8, implementation-data-type=uint8, transfer-property=PENDING
          signal CAN3_Rr_Coolanttemp: start 144, 9 bit, big-endian, i-signal-type=PRIMITIVE, init-value=constant-reference=Init_CAN3_Rr_Coolanttemp, base-type=uint16, implementation-data-type=uint16, transfer-property=PENDING
          signal CAN3_sigAirIntenZon1St: start 31, 4 bit, big-endian, i-signal-type=PRIMITIVE, init-value=constant-reference=Init_CAN3_sigAirIntenZon1St, base-type=uint8, implementation-data-type=uint8, transfer-property=PENDING
          signal CAN3_sigAirIntenZon3St: start 27, 4 bit, big-endian, i-signal-type=PRIMITIVE, init-value=constant-reference=Init_CAN3_sigAirIntenZon3St, base-type=uint8, implementation-data-type=uint8, transfer-property=PENDING
          signal CAN3_sigAmbAirT: start 95, 8 bit, big-endian, i-signal-type=PRIMITIVE, init-value=constant-reference=Init_CAN3_sigAmbAirT, base-type=uint8, implementation-data-type=uint8, transfer-property=PENDING
          signal CAN3_sigCbnAirT: start 87, 8 bit, big-endian, i-signal-type=PRIMITIVE, init-value=constant-reference=Init_CAN3_sigCbnAirT, base-type=uint8, implementation-data-type=uint8, transfer-property=PENDING
          signal CAN3_sigCbnPTCPwrAct: start 79, 8 bit, big-endian, i-signal-type=PRIMITIVE, init-value=constant-reference=Init_CAN3_sigCbnPTCPwrAct, base-type=uint8, implementation-data-type=uint8, transfer-property=PENDING
          signal CAN3_sigCbnSolarLeft: start 127, 8 bit, big-endian, i-signal-type=PRIMITIVE, init-value=constant-reference=Init_CAN3_sigCbnSolarLeft, base-type=uint8, implementation-data-type=uint8, transfer-property=PENDING
          signal CAN3_sigCbnSolarRight: start 103, 8 bit, big-endian, i-signal-type=PRIMITIVE, init-value=constant-reference=Init_CAN3_sigCbnSolarRight, base-type=uint8, implementation-data-type=uint8, transfer-property=PENDING
          signal CAN3_sigClmtCmprPwrAct: start 71, 8 bit, big-endian, i-signal-type=PRIMITIVE, init-value=constant-reference=Init_CAN3_sigClmtCmprPwrAct, base-type=uint8, implementation-data-type=uint8, transfer-property=PENDING
          signal CAN3_sigClntTHvBattOut: start 135, 8 bit, big-endian, i-signal-type=PRIMITIVE, init-value=constant-reference=Init_CAN3_sigClntTHvBattOut, base-type=uint8, implementation-data-type=uint8, transfer-property=PENDING
          signal CAN3_sigDfrstSt: start 38, 1 bit, big-endian, i-signal-type=PRIMITIVE, init-value=constant-reference=Init_CAN3_sigDfrstSt, base-type=uint8, implementation-data-type=uint8, transfer-property=PENDING
          signal CAN3_sigHvacSt: start 46, 1 bit, big-endian, i-signal-type=PRIMITIVE, init-value=constant-reference=Init_CAN3_sigHvacSt, base-type=uint8, implementation-data-type=uint8, transfer-property=PENDING
          signal CAN3_sigRecircSt: start 47, 1 bit, big-endian, i-signal-type=PRIMITIVE, init-value=constant-reference=Init_CAN3_sigRecircSt, base-type=uint8, implementation-data-type=uint8, transfer-property=PENDING
          signal CAN3_sigSetTempZon1St: start 53, 6 bit, big-endian, i-signal-type=PRIMITIVE, init-value=constant-reference=Init_CAN3_sigSetTempZon1St, base-type=uint8, implementation-data-type=uint8, transfer-property=PENDING
          signal CAN3_sigSetTempZon2St: start 45, 6 bit, big-endian, i-signal-type=PRIMITIVE, init-value=constant-reference=Init_CAN3_sigSetTempZon2St, base-type=uint8, implementation-data-type=uint8, transfer-property=PENDING
          signal CAN3_sigSetTempZon3St: start 37, 6 bit, big-endian, i-signal-type=PRIMITIVE, init-value=constant-reference=Init_CAN3_sigSetTempZon3St, base-type=uint8, implementation-data-type=uint8, transfer-property=PENDING
          signal CAN3_sigWindDirZon1St: start 22, 3 bit, big-endian, i-signal-type=PRIMITIVE, init-value=constant-reference=Init_CAN3_sigWindDirZon1St, base-type=uint8, implementation-data-type=uint8, transfer-property=PENDING
          signal CAN3_sigWindDirZon3St: start 18, 3 bit, big-endian, i-signal-type=PRIMITIVE, init-value=constant-reference=Init_CAN3_sigWindDirZon3St, base-type=uint8, implementation-data-type=uint8, transfer-property=PENDING
      frame CAN3_FD_THCM2: id 0x186, frame-length=20, can-addressing-mode=STANDARD, can-fd-frame-support=true, can-frame-rx-behavior=CAN-FD, can-frame-tx-behavior=CAN-FD
        pdu CAN3_FD_THCM2: length=20, minimum-delay=0.0, transmission-mode-true-timing={cyclic-timing=time-period=0.1, event-controlled-timing={number-of-repetitions=0, repetition-period=0.01}}, unused-bit-pattern=0
          mapping CAN3_SG_FD_THCM2: i-signal-group=CAN3_SG_FD_THCM2, start-position=0, transfer-property=TRIGGERED-ON-CHANGE
          signal CAN3_ACSubMode: start 11, 3 bit, big-endian, i-signal-type=PRIMITIVE, init-value=constant-reference=Init_CAN3_ACSubMode, base-type=uint8, implementation-data-type=uint8, transfer-property=PENDING
          signal CAN3_APTC_ActFrRiPwr: start 143, 8 bit, big-endian, i-signal-type=PRIMITIVE, init-value=constant-reference=Init_CAN3_APTC_ActFrRiPwr, base-type=uint8, implementation-data-type=uint8, transfer-property=TRIGGERED-ON-CHANGE
          signal CAN3_BatLoopActWtFlw: start 151, 8 bit, big-endian, i-signal-type=PRIMITIVE, init-value=constant-reference=Init_CAN3_BatLoopActWtFlw, base-type=uint8, implementation-data-type=uint8, transfer-property=PENDING
          signal CAN3_CCU_CbnPreACWkSts: start 35, 2 bit, big-endian, i-signal-type=PRIMITIVE, init-value=constant-reference=Init_CAN3_CCU_CbnPreACWkSts, base-type=uint8, implementation-data-type=uint8, transfer-property=PENDING
          signal CAN3_CCU_CbnPreEstimdTi: start 55, 6 bit, big-endian, i-signal-type=PRIMITIVE, init-value=constant-reference=Init_CAN3_CCU_CbnPreEstimdTi, base-type=uint8, implementation-data-type=uint8, transfer-property=PENDING
          signal CAN3_CCU_CbnPreSts: start 39, 2 bit, big-endian, i-signal-type=PRIMITIVE, init-value=constant-reference=Init_CAN3_CCU_CbnPreSts, base-type=uint8, implementation-data-type=uint8, transfer-property=PENDING
          signal CAN3_CCU_HiVoltageReq: start 23, 1 bit, big-endian, i-signal-type=PRIMITIVE, init-value=constant-reference=Init_CAN3_CCU_HiVoltageReq, base-type=uint8, implementation-data-type=uint8, transfer-property=PENDING
          signal CAN3_CoolgFanActDuty: start 159, 8 bit, big-endian, i-signal-type=PRIMITIVE, init-value=constant-reference=Init_CAN3_CoolgFanActDuty, base-type=uint8, implementation-data-type=uint8, transfer-property=TRIGGERED-ON-CHANGE
          signal CAN3_DeiceModReq: start 37, 2 bit, big-endian, i-signal-type=PRIMITIVE, init-value=constant-reference=Init_CAN3_DeiceModReq, base-type=uint8, implementation-data-type=uint8, transfer-property=PENDING
          signal CAN3_FD_Blower_Cmd: start 7, 8 bit, big-endian, i-signal-type=PRIMITIVE, init-value=constant-reference=Init_CAN3_FD_Blower_Cmd, base-type=uint8, implementation-data-type=uint8, transfer-property=TRIGGERED-ON-CHANGE
          signal CAN3_FD_Comp_Cmd: start 22, 15 bit, big-endian, i-signal-type=PRIMITIVE, init-value=constant-reference=Init_CAN3_FD_Comp_Cmd, base-type=uint16, implementation-data-type=uint16, transfer-property=TRIGGERED-ON-CHANGE
          signal CAN3_FD_EWP1_Cmd: start 135, 8 bit, big-endian, i-signal-type=PRIMITIVE, init-value=constant-reference=Init_CAN3_FD_EWP1_Cmd, base-type=uint8, implementation-data-type=uint8, transfer-property=PENDING
          signal CAN3_FD_EWP2_Cmd: start 127, 8 bit, big-endian, i-signal-type=PRIMITIVE, init-value=constant-reference=Init_CAN3_FD_EWP2_Cmd, base-type=uint8, implementation-data-type=uint8, transfer-property=PENDING
          signal CAN3_FD_EWP3_Cmd: start 119, 8 bit, big-endian, i-signal-type=PRIMITIVE, init-value=constant-reference=Init_CAN3_FD_EWP3_Cmd, base-type=uint8, implementation-data-type=uint8, transfer-property=PENDING
          signal CAN3_FD_EXV1_Cmd: start 33, 10 bit, big-endian, i-signal-type=PRIMITIVE, init-value=constant-reference=Init_CAN3_FD_EXV1_Cmd, base-type=uint16, implementation-data-type=uint16, transfer-property=PENDING
          signal CAN3_FD_EXV2_Cmd: start 49, 10 bit, big-endian, i-signal-type=PRIMITIVE, init-value=constant-reference=Init_CAN3_FD_EXV2_Cmd, base-type=uint16, implementation-data-type=uint16, transfer-property=PENDING
          signal CAN3_FD_FWV_Cmd: start 8, 1 bit, big-endian, i-signal-type=PRIMITIVE, init-value=constant-reference=Init_CAN3_FD_FWV_Cmd, base-type=uint8, implementation-data-type=uint8, transfer-property=PENDING
          signal CAN3_FD_FrLeAPTCHeatPwr_Cmd: start 87, 8 bit, big-endian, i-signal-type=PRIMITIVE, init-value=constant-reference=Init_CAN3_FD_FrLeAPTCHeatPwr_Cmd, base-type=uint8, implementation-data-type=uint8, transfer-property=TRIGGERED-ON-CHANGE
          signal CAN3_FD_FrRiAPTCHeatPwr_Cmd: start 79, 8 bit, big-endian, i-signal-type=PRIMITIVE, init-value=constant-reference=Init_CAN3_FD_FrRiAPTCHeatPwr_Cmd, base-type=uint8, implementation-data-type=uint8, transfer-property=TRIGGERED-ON-CHANGE
          signal CAN3_FD_FrWPTCHeatPwr_Cmd: start 103, 16 bit, big-endian, i-signal-type=PRIMITIVE, init-value=constant-reference=Init_CAN3_FD_FrWPTCHeatPwr_Cmd, base-type=uint16, implementation-data-type=uint16, transfer-property=TRIGGERED-ON-CHANGE
          signal CAN3_FD_RrAPTCHeatPwr_Cmd: start 95, 8 bit, big-endian, i-signal-type=PRIMITIVE, init-value=constant-reference=Init_CAN3_FD_RrAPTCHeatPwr_Cmd, base-type=uint8, implementation-data-type=uint8, transfer-property=TRIGGERED-ON-CHANGE
          signal CAN3_FD_SOTXV_Cmd: start 12, 1 bit, big-endian, i-signal-type=PRIMITIVE, init-value=constant-reference=Init_CAN3_FD_SOTXV_Cmd, base-type=uint8, implementation-data-type=uint8, transfer-property=PENDING
          signal CAN3_FD_SOV1_Cmd: start 13, 1 bit, big-endian, i-signal-type=PRIMITIVE, init-value=constant-reference=Init_CAN3_FD_SOV1_Cmd, base-type=uint8, implementation-data-type=uint8, transfer-property=PENDING
          signal CAN3_FD_SOV2_Cmd: start 14, 1 bit, big-endian, i-signal-type=PRIMITIVE, init-value=constant-reference=Init_CAN3_FD_SOV2_Cmd, base-type=uint8, implementation-data-type=uint8, transfer-property=PENDING
          signal CAN3_FD_SOV3_Cmd: start 15, 1 bit, big-endian, i-signal-type=PRIMITIVE, init-value=constant-reference=Init_CAN3_FD_SOV3_Cmd, base-type=uint8, implementation-data-type=uint8, transfer-property=PENDING
          signal CAN3_FD_TWV_Cmd: start 71, 8 bit, big-endian, i-signal-type=PRIMITIVE, init-value=constant-reference=Init_CAN3_FD_TWV_Cmd, base-type=uint8, implementation-data-type=uint8, transfer-property=PENDING
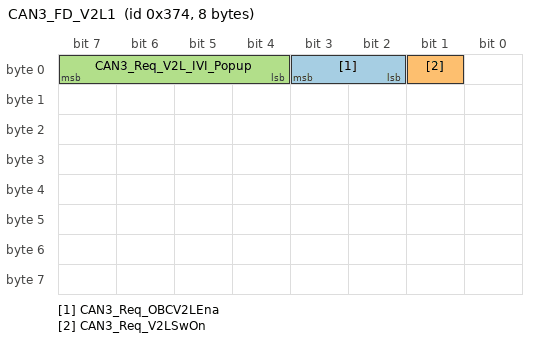
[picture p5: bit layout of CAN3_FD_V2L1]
      frame CAN3_FD_V2L1: id 0x374, frame-length=8, can-addressing-mode=STANDARD, can-fd-frame-support=true, can-frame-rx-behavior=CAN-FD, can-frame-tx-behavior=CAN-FD
        pdu CAN3_FD_V2L1: length=8, minimum-delay=0.0, transmission-mode-true-timing={cyclic-timing=time-period=0.1, event-controlled-timing={number-of-repetitions=0, repetition-period=0.01}}, unused-bit-pattern=0
          mapping CAN3_SG_FD_V2L1: i-signal-group=CAN3_SG_FD_V2L1, start-position=0, transfer-property=TRIGGERED-ON-CHANGE
          signal CAN3_Req_OBCV2LEna: start 3, 2 bit, big-endian, i-signal-type=PRIMITIVE, init-value=constant-reference=Init_CAN3_Req_OBCV2LEna, base-type=uint8, implementation-data-type=uint8, transfer-property=PENDING
          signal CAN3_Req_V2LSwOn: start 1, 1 bit, big-endian, i-signal-type=PRIMITIVE, init-value=constant-reference=Init_CAN3_Req_V2LSwOn, base-type=uint8, implementation-data-type=uint8, transfer-property=TRIGGERED-ON-CHANGE
          signal CAN3_Req_V2L_IVI_Popup: start 7, 4 bit, big-endian, i-signal-type=PRIMITIVE, init-value=constant-reference=Init_CAN3_Req_V2L_IVI_Popup, base-type=uint8, implementation-data-type=uint8, transfer-property=TRIGGERED-ON-CHANGE
      frame CAN3_FD_VCU0: id 0x1F0, frame-length=64, can-addressing-mode=STANDARD, can-fd-frame-support=true, can-frame-rx-behavior=CAN-FD, can-frame-tx-behavior=CAN-FD
        pdu CAN3_FD_VCU0: length=64, minimum-delay=0.0, transmission-mode-true-timing=cyclic-timing=time-period=0.01, unused-bit-pattern=0
          mapping CAN3_SG_FD_VCU0: i-signal-group=CAN3_SG_FD_VCU0, start-position=0, transfer-property=PENDING
          signal CAN3_EVCCAplusPwrUpReq: start 94, 1 bit, big-endian, i-signal-type=PRIMITIVE, init-value=constant-reference=Init_CAN3_EVCCAplusPwrUpReq, base-type=uint8, implementation-data-type=uint8, transfer-property=PENDING
          signal CAN3_FDADC12VDet: start 135, 8 bit, big-endian, i-signal-type=PRIMITIVE, init-value=constant-reference=Init_CAN3_FDADC12VDet, base-type=uint8, implementation-data-type=uint8, transfer-property=PENDING
          signal CAN3_FDADC12VDetAvg: start 127, 8 bit, big-endian, i-signal-type=PRIMITIVE, init-value=constant-reference=Init_CAN3_FDADC12VDetAvg, base-type=uint8, implementation-data-type=uint8, transfer-property=PENDING
          signal CAN3_FDC_VCU_ActMaxSlideRate_Sta: start 183, 16 bit, big-endian, i-signal-type=PRIMITIVE, init-value=constant-reference=Init_CAN3_FDC_VCU_ActMaxSlideRate_Sta, base-type=uint16, implementation-data-type=uint16, transfer-property=PENDING
          signal CAN3_FDC_VCU_AllowMovThd_OTA_Sta: start 111, 2 bit, big-endian, i-signal-type=PRIMITIVE, init-value=constant-reference=Init_CAN3_FDC_VCU_AllowMovThd_OTA_Sta, base-type=uint8, implementation-data-type=uint8, transfer-property=PENDING
          signal CAN3_FDC_VCU_DTCCarousel_Sta: start 143, 8 bit, big-endian, i-signal-type=PRIMITIVE, init-value=constant-reference=Init_CAN3_FDC_VCU_DTCCarousel_Sta, base-type=uint8, implementation-data-type=uint8, transfer-property=PENDING
          signal CAN3_FDC_VCU_ForceP_Cmd: start 24, 1 bit, big-endian, i-signal-type=PRIMITIVE, init-value=constant-reference=Init_CAN3_FDC_VCU_ForceP_Cmd, base-type=uint8, implementation-data-type=uint8, transfer-property=PENDING
          signal CAN3_FDC_VCU_PwrReq_OTA_Sta: start 109, 2 bit, big-endian, i-signal-type=PRIMITIVE, init-value=constant-reference=Init_CAN3_FDC_VCU_PwrReq_OTA_Sta, base-type=uint8, implementation-data-type=uint8, transfer-property=PENDING
          signal CAN3_FDC_VCU_RWDRDCActive_Sta: start 93, 2 bit, big-endian, i-signal-type=PRIMITIVE, init-value=constant-reference=Init_CAN3_FDC_VCU_RWDRDCActive_Sta, base-type=uint8, implementation-data-type=uint8, transfer-property=PENDING
          signal CAN3_FDC_VCU_RegenTqLimitEn_Sta: start 23, 1 bit, big-endian, i-signal-type=PRIMITIVE, init-value=constant-reference=Init_CAN3_FDC_VCU_RegenTqLimitEn_Sta, base-type=uint8, implementation-data-type=uint8, transfer-property=PENDING
          signal CAN3_FDC_VCU_SlideRegenLimTq_Sta: start 199, 16 bit, big-endian, i-signal-type=PRIMITIVE, init-value=constant-reference=Init_CAN3_FDC_VCU_SlideRegenLimTq_Sta, base-type=uint16, implementation-data-type=uint16, transfer-property=PENDING
          signal CAN3_FDC_VCU_VehActSpd_Sta: start 167, 16 bit, big-endian, i-signal-type=PRIMITIVE, init-value=constant-reference=Init_CAN3_FDC_VCU_VehActSpd_Sta, base-type=uint16, implementation-data-type=uint16, transfer-property=PENDING
          signal CAN3_FDC_VCU_VehMalfunLevel_Sta: start 3, 4 bit, big-endian, i-signal-type=PRIMITIVE, init-value=constant-reference=Init_CAN3_FDC_VCU_VehMalfunLevel_Sta, base-type=uint8, implementation-data-type=uint8, transfer-property=PENDING
          signal CAN3_FDC_VMC_ActStESCYaw_Sta: start 215, 16 bit, big-endian, i-signal-type=PRIMITIVE, init-value=constant-reference=Init_CAN3_FDC_VMC_ActStESCYaw_Sta, base-type=uint16, implementation-data-type=uint16, transfer-property=PENDING
          signal CAN3_FDC_VMC_AntiSpdLimEn_Sta: start 68, 1 bit, big-endian, i-signal-type=PRIMITIVE, init-value=constant-reference=Init_CAN3_FDC_VMC_AntiSpdLimEn_Sta, base-type=uint8, implementation-data-type=uint8, transfer-property=PENDING
          signal CAN3_FDC_VMC_LongAcc_Sta: start 151, 16 bit, big-endian, i-signal-type=PRIMITIVE, init-value=constant-reference=Init_CAN3_FDC_VMC_LongAcc_Sta, base-type=uint16, implementation-data-type=uint16, transfer-property=PENDING
          signal CAN3_Fr_TqSource: start 47, 4 bit, big-endian, i-signal-type=PRIMITIVE, init-value=constant-reference=Init_CAN3_Fr_TqSource, base-type=uint8, implementation-data-type=uint8, transfer-property=PENDING
          signal CAN3_HVRlyOpFail: start 56, 1 bit, big-endian, i-signal-type=PRIMITIVE, init-value=constant-reference=Init_CAN3_HVRlyOpFail, base-type=uint8, implementation-data-type=uint8, transfer-property=PENDING
          signal CAN3_HVTHCMSysAvail: start 41, 2 bit, big-endian, i-signal-type=PRIMITIVE, init-value=constant-reference=Init_CAN3_HVTHCMSysAvail, base-type=uint8, implementation-data-type=uint8, transfer-property=PENDING
          signal CAN3_LVBattChrgtimeAct: start 107, 12 bit, big-endian, i-signal-type=PRIMITIVE, init-value=constant-reference=Init_CAN3_LVBattChrgtimeAct, base-type=uint16, implementation-data-type=uint16, transfer-property=PENDING
          signal CAN3_LVBattVoltSta: start 43, 2 bit, big-endian, i-signal-type=PRIMITIVE, init-value=constant-reference=Init_CAN3_LVBattVoltSta, base-type=uint8, implementation-data-type=uint8, transfer-property=PENDING
          signal CAN3_LVChrgHoldTAct: start 91, 12 bit, big-endian, i-signal-type=PRIMITIVE, init-value=constant-reference=Init_CAN3_LVChrgHoldTAct, base-type=uint16, implementation-data-type=uint16, transfer-property=PENDING
          signal CAN3_LVSilentChrgLv: start 83, 2 bit, big-endian, i-signal-type=PRIMITIVE, init-value=constant-reference=Init_CAN3_LVSilentChrgLv, base-type=uint8, implementation-data-type=uint8, transfer-property=PENDING
          signal CAN3_LVSilentChrgReq: start 81, 1 bit, big-endian, i-signal-type=PRIMITIVE, init-value=constant-reference=Init_CAN3_LVSilentChrgReq, base-type=uint8, implementation-data-type=uint8, transfer-property=PENDING
          signal CAN3_LVSilentChrgSta: start 85, 2 bit, big-endian, i-signal-type=PRIMITIVE, init-value=constant-reference=Init_CAN3_LVSilentChrgSta, base-type=uint8, implementation-data-type=uint8, transfer-property=PENDING
          signal CAN3_MCUActDisFail: start 71, 1 bit, big-endian, i-signal-type=PRIMITIVE, init-value=constant-reference=Init_CAN3_MCUActDisFail, base-type=uint8, implementation-data-type=uint8, transfer-property=PENDING
          signal CAN3_PMMAllowECUSleep: start 95, 1 bit, big-endian, i-signal-type=PRIMITIVE, init-value=constant-reference=Init_CAN3_PMMAllowECUSleep, base-type=uint8, implementation-data-type=uint8, transfer-property=PENDING
          signal CAN3_PowerDownFault: start 19, 4 bit, big-endian, i-signal-type=PRIMITIVE, init-value=constant-reference=Init_CAN3_PowerDownFault, base-type=uint8, implementation-data-type=uint8, transfer-property=PENDING
          signal CAN3_PowerDownState: start 22, 3 bit, big-endian, i-signal-type=PRIMITIVE, init-value=constant-reference=Init_CAN3_PowerDownState, base-type=uint8, implementation-data-type=uint8, transfer-property=PENDING
          signal CAN3_PowerUpFault: start 11, 4 bit, big-endian, i-signal-type=PRIMITIVE, init-value=constant-reference=Init_CAN3_PowerUpFault, base-type=uint8, implementation-data-type=uint8, transfer-property=PENDING
          signal CAN3_PowerUpState: start 15, 4 bit, big-endian, i-signal-type=PRIMITIVE, init-value=constant-reference=Init_CAN3_PowerUpState, base-type=uint8, implementation-data-type=uint8, transfer-property=PENDING
          signal CAN3_PwrDownReq: start 37, 2 bit, big-endian, i-signal-type=PRIMITIVE, init-value=constant-reference=Init_CAN3_PwrDownReq, base-type=uint8, implementation-data-type=uint8, transfer-property=PENDING
          signal CAN3_PwrStaConstraint: start 29, 3 bit, big-endian, i-signal-type=PRIMITIVE, init-value=constant-reference=Init_CAN3_PwrStaConstraint, base-type=uint8, implementation-data-type=uint8, transfer-property=PENDING
          signal CAN3_PwrStaONTOIVIPopReq: start 70, 1 bit, big-endian, i-signal-type=PRIMITIVE, init-value=constant-reference=Init_CAN3_PwrStaONTOIVIPopReq, base-type=uint8, implementation-data-type=uint8, transfer-property=PENDING
          signal CAN3_PwrStaONTOIVIPopT: start 67, 12 bit, big-endian, i-signal-type=PRIMITIVE, init-value=constant-reference=Init_CAN3_PwrStaONTOIVIPopT, base-type=uint16, implementation-data-type=uint16, transfer-property=PENDING
          signal CAN3_PwrStaSelect: start 31, 2 bit, big-endian, i-signal-type=PRIMITIVE, init-value=constant-reference=Init_CAN3_PwrStaSelect, base-type=uint8, implementation-data-type=uint8, transfer-property=PENDING
          signal CAN3_PwrStaTOSta: start 69, 1 bit, big-endian, i-signal-type=PRIMITIVE, init-value=constant-reference=Init_CAN3_PwrStaTOSta, base-type=uint8, implementation-data-type=uint8, transfer-property=PENDING
          signal CAN3_PwrUpReq: start 39, 2 bit, big-endian, i-signal-type=PRIMITIVE, init-value=constant-reference=Init_CAN3_PwrUpReq, base-type=uint8, implementation-data-type=uint8, transfer-property=PENDING
          signal CAN3_Rr_TqSource: start 35, 4 bit, big-endian, i-signal-type=PRIMITIVE, init-value=constant-reference=Init_CAN3_Rr_TqSource, base-type=uint8, implementation-data-type=uint8, transfer-property=PENDING
          signal CAN3_SchedChgTOSta: start 87, 1 bit, big-endian, i-signal-type=PRIMITIVE, init-value=constant-reference=Init_CAN3_SchedChgTOSta, base-type=uint8, implementation-data-type=uint8, transfer-property=PENDING
          signal CAN3_SilentChkAllowSleep: start 86, 1 bit, big-endian, i-signal-type=PRIMITIVE, init-value=constant-reference=Init_CAN3_SilentChkAllowSleep, base-type=uint8, implementation-data-type=uint8, transfer-property=PENDING
          signal CAN3_SysAllowReadySta: start 57, 1 bit, big-endian, i-signal-type=PRIMITIVE, init-value=constant-reference=Init_CAN3_SysAllowReadySta, base-type=uint8, implementation-data-type=uint8, transfer-property=PENDING
          signal CAN3_SysPwrSta: start 7, 4 bit, big-endian, i-signal-type=PRIMITIVE, init-value=constant-reference=Init_CAN3_SysPwrSta, base-type=uint8, implementation-data-type=uint8, transfer-property=PENDING
          signal CAN3_TCountSta: start 26, 2 bit, big-endian, i-signal-type=PRIMITIVE, init-value=constant-reference=Init_CAN3_TCountSta, base-type=uint8, implementation-data-type=uint8, transfer-property=PENDING
          signal CAN3_TimerAllowSleep: start 80, 1 bit, big-endian, i-signal-type=PRIMITIVE, init-value=constant-reference=Init_CAN3_TimerAllowSleep, base-type=uint8, implementation-data-type=uint8, transfer-property=PENDING
          signal CAN3_VCUBrkSWSta: start 63, 2 bit, big-endian, i-signal-type=PRIMITIVE, init-value=constant-reference=Init_CAN3_VCUBrkSWSta, base-type=uint8, implementation-data-type=uint8, transfer-property=PENDING
          signal CAN3_VCUFLDoorSta: start 61, 1 bit, big-endian, i-signal-type=PRIMITIVE, init-value=constant-reference=Init_CAN3_VCUFLDoorSta, base-type=uint8, implementation-data-type=uint8, transfer-property=PENDING
          signal CAN3_VCUFRDoorSta: start 60, 1 bit, big-endian, i-signal-type=PRIMITIVE, init-value=constant-reference=Init_CAN3_VCUFRDoorSta, base-type=uint8, implementation-data-type=uint8, transfer-property=PENDING
          signal CAN3_VCURLDoorSta: start 59, 1 bit, big-endian, i-signal-type=PRIMITIVE, init-value=constant-reference=Init_CAN3_VCURLDoorSta, base-type=uint8, implementation-data-type=uint8, transfer-property=PENDING
          signal CAN3_VCURRDoorSta: start 58, 1 bit, big-endian, i-signal-type=PRIMITIVE, init-value=constant-reference=Init_CAN3_VCURRDoorSta, base-type=uint8, implementation-data-type=uint8, transfer-property=PENDING
          signal CAN3_VehHVPwrAvail4THCM: start 55, 8 bit, big-endian, i-signal-type=PRIMITIVE, init-value=constant-reference=Init_CAN3_VehHVPwrAvail4THCM, base-type=uint8, implementation-data-type=uint8, transfer-property=PENDING
      frame CAN3_FD_VCU1: id 0x116, frame-length=8, can-addressing-mode=STANDARD, can-fd-frame-support=true, can-frame-rx-behavior=CAN-FD, can-frame-tx-behavior=CAN-FD
        pdu CAN3_FD_VCU1: length=8, minimum-delay=0.0, transmission-mode-true-timing=event-controlled-timing={number-of-repetitions=0, repetition-period=0.01}, unused-bit-pattern=0
          mapping CAN3_SG_FD_VCU1: i-signal-group=CAN3_SG_FD_VCU1, start-position=0, transfer-property=TRIGGERED
          signal CAN3_ActiveDischReq: start 44, 1 bit, big-endian, i-signal-type=PRIMITIVE, init-value=constant-reference=Init_CAN3_ActiveDischReq, base-type=uint8, implementation-data-type=uint8, transfer-property=TRIGGERED
          signal CAN3_CS_VCU1: start 7, 8 bit, big-endian, i-signal-type=PRIMITIVE, init-value=constant-reference=Init_CAN3_CS_VCU1, base-type=uint8, implementation-data-type=uint8, transfer-property=TRIGGERED
          signal CAN3_CoastDwModeStaChk: start 19, 2 bit, big-endian, i-signal-type=PRIMITIVE, init-value=constant-reference=Init_CAN3_CoastDwModeStaChk, base-type=uint8, implementation-data-type=uint8, transfer-property=TRIGGERED
          signal CAN3_DCDCEnaReq: start 40, 1 bit, big-endian, i-signal-type=PRIMITIVE, init-value=constant-reference=Init_CAN3_DCDCEnaReq, base-type=uint8, implementation-data-type=uint8, transfer-property=TRIGGERED
          signal CAN3_DCDCVoltSetpoint: start 55, 8 bit, big-endian, i-signal-type=PRIMITIVE, init-value=constant-reference=Init_CAN3_DCDCVoltSetpoint, base-type=uint8, implementation-data-type=uint8, transfer-property=TRIGGERED
          signal CAN3_DemoModeStaChk: start 17, 2 bit, big-endian, i-signal-type=PRIMITIVE, init-value=constant-reference=Init_CAN3_DemoModeStaChk, base-type=uint8, implementation-data-type=uint8, transfer-property=TRIGGERED
          signal CAN3_Dr_SeatSta: start 23, 2 bit, big-endian, i-signal-type=PRIMITIVE, init-value=constant-reference=Init_CAN3_Dr_SeatSta, base-type=uint8, implementation-data-type=uint8, transfer-property=TRIGGERED
          signal CAN3_DynoModeStaChk: start 21, 2 bit, big-endian, i-signal-type=PRIMITIVE, init-value=constant-reference=Init_CAN3_DynoModeStaChk, base-type=uint8, implementation-data-type=uint8, transfer-property=TRIGGERED
          signal CAN3_Fr_ActvDmpDisabReq: start 46, 1 bit, big-endian, i-signal-type=PRIMITIVE, init-value=constant-reference=Init_CAN3_Fr_ActvDmpDisabReq, base-type=uint8, implementation-data-type=uint8, transfer-property=TRIGGERED
          signal CAN3_Fr_MCUEnaReq: start 41, 1 bit, big-endian, i-signal-type=PRIMITIVE, init-value=constant-reference=Init_CAN3_Fr_MCUEnaReq, base-type=uint8, implementation-data-type=uint8, transfer-property=TRIGGERED
          signal CAN3_HVBatCnctReq: start 43, 1 bit, big-endian, i-signal-type=PRIMITIVE, init-value=constant-reference=Init_CAN3_HVBatCnctReq, base-type=uint8, implementation-data-type=uint8, transfer-property=TRIGGERED
          signal CAN3_HVSysReadyToCharge: start 33, 2 bit, big-endian, i-signal-type=PRIMITIVE, init-value=constant-reference=Init_CAN3_HVSysReadyToCharge, base-type=uint8, implementation-data-type=uint8, transfer-property=TRIGGERED
          signal CAN3_LVChrgFuncStaChk: start 25, 2 bit, big-endian, i-signal-type=PRIMITIVE, init-value=constant-reference=Init_CAN3_LVChrgFuncStaChk, base-type=uint8, implementation-data-type=uint8, transfer-property=TRIGGERED
          signal CAN3_MSA_Crl_Sta: start 31, 3 bit, big-endian, i-signal-type=PRIMITIVE, init-value=constant-reference=Init_CAN3_MSA_Crl_Sta, base-type=uint8, implementation-data-type=uint8, transfer-property=TRIGGERED
          signal CAN3_PrkReq: start 45, 1 bit, big-endian, i-signal-type=PRIMITIVE, init-value=constant-reference=Init_CAN3_PrkReq, base-type=uint8, implementation-data-type=uint8, transfer-property=TRIGGERED
          signal CAN3_PwrSta: start 63, 3 bit, big-endian, i-signal-type=PRIMITIVE, init-value=constant-reference=Init_CAN3_PwrSta, base-type=uint8, implementation-data-type=uint8, transfer-property=TRIGGERED
          signal CAN3_RC_VCU1: start 15, 4 bit, big-endian, i-signal-type=PRIMITIVE, init-value=constant-reference=Init_CAN3_RC_VCU1, base-type=uint8, implementation-data-type=uint8, transfer-property=TRIGGERED
          signal CAN3_Rr_ActvDmpDisabReq: start 47, 1 bit, big-endian, i-signal-type=PRIMITIVE, init-value=constant-reference=Init_CAN3_Rr_ActvDmpDisabReq, base-type=uint8, implementation-data-type=uint8, transfer-property=TRIGGERED
          signal CAN3_Rr_MCUEnaReq: start 42, 1 bit, big-endian, i-signal-type=PRIMITIVE, init-value=constant-reference=Init_CAN3_Rr_MCUEnaReq, base-type=uint8, implementation-data-type=uint8, transfer-property=TRIGGERED
          signal CAN3_ShiftGearPosn: start 38, 3 bit, big-endian, i-signal-type=PRIMITIVE, init-value=constant-reference=Init_CAN3_ShiftGearPosn, base-type=uint8, implementation-data-type=uint8, transfer-property=TRIGGERED
      frame CAN3_FD_VCU2: id 0x154, frame-length=24, can-addressing-mode=STANDARD, can-fd-frame-support=true, can-frame-rx-behavior=CAN-FD, can-frame-tx-behavior=CAN-FD
        pdu CAN3_FD_VCU2: length=24, minimum-delay=0.0, transmission-mode-true-timing=cyclic-timing=time-period=0.01, unused-bit-pattern=0
          mapping CAN3_SG_FD_VCU2: i-signal-group=CAN3_SG_FD_VCU2, start-position=0, transfer-property=PENDING
          signal CAN3_CS_VCU2_CAN1: start 7, 8 bit, big-endian, i-signal-type=PRIMITIVE, init-value=constant-reference=Init_CAN3_CS_VCU2_CAN1, base-type=uint8, implementation-data-type=uint8, transfer-property=PENDING
          signal CAN3_Fr_IdcMax: start 151, 12 bit, big-endian, i-signal-type=PRIMITIVE, init-value=constant-reference=Init_CAN3_Fr_IdcMax, base-type=uint16, implementation-data-type=uint16, transfer-property=PENDING
          signal CAN3_Fr_IdcMin: start 155, 12 bit, big-endian, i-signal-type=PRIMITIVE, init-value=constant-reference=Init_CAN3_Fr_IdcMin, base-type=uint16, implementation-data-type=uint16, transfer-property=PENDING
          signal CAN3_Fr_TMTqReq: start 135, 16 bit, big-endian, i-signal-type=PRIMITIVE, init-value=constant-reference=Init_CAN3_Fr_TMTqReq, base-type=uint16, implementation-data-type=uint16, transfer-property=PENDING
          signal CAN3_Fr_TorqMax: start 175, 12 bit, big-endian, i-signal-type=PRIMITIVE, init-value=constant-reference=Init_CAN3_Fr_TorqMax, base-type=uint16, implementation-data-type=uint16, transfer-property=PENDING
          signal CAN3_Fr_TorqMin: start 179, 12 bit, big-endian, i-signal-type=PRIMITIVE, init-value=constant-reference=Init_CAN3_Fr_TorqMin, base-type=uint16, implementation-data-type=uint16, transfer-property=PENDING
          signal CAN3_Fr_UdcMax: start 95, 12 bit, big-endian, i-signal-type=PRIMITIVE, init-value=constant-reference=Init_CAN3_Fr_UdcMax, base-type=uint16, implementation-data-type=uint16, transfer-property=PENDING
          signal CAN3_Fr_UdcMin: start 99, 12 bit, big-endian, i-signal-type=PRIMITIVE, init-value=constant-reference=Init_CAN3_Fr_UdcMin, base-type=uint16, implementation-data-type=uint16, transfer-property=PENDING
          signal CAN3_RC_VCU2_CAN1: start 15, 4 bit, big-endian, i-signal-type=PRIMITIVE, init-value=constant-reference=Init_CAN3_RC_VCU2_CAN1, base-type=uint8, implementation-data-type=uint8, transfer-property=PENDING
          signal CAN3_Rr_IdcMax: start 23, 12 bit, big-endian, i-signal-type=PRIMITIVE, init-value=constant-reference=Init_CAN3_Rr_IdcMax, base-type=uint16, implementation-data-type=uint16, transfer-property=PENDING
          signal CAN3_Rr_IdcMin: start 27, 12 bit, big-endian, i-signal-type=PRIMITIVE, init-value=constant-reference=Init_CAN3_Rr_IdcMin, base-type=uint16, implementation-data-type=uint16, transfer-property=PENDING
          signal CAN3_Rr_TMTqReq: start 119, 16 bit, big-endian, i-signal-type=PRIMITIVE, init-value=constant-reference=Init_CAN3_Rr_TMTqReq, base-type=uint16, implementation-data-type=uint16, transfer-property=PENDING
          signal CAN3_Rr_TorqMax: start 47, 12 bit, big-endian, i-signal-type=PRIMITIVE, init-value=constant-reference=Init_CAN3_Rr_TorqMax, base-type=uint16, implementation-data-type=uint16, transfer-property=PENDING
          signal CAN3_Rr_TorqMin: start 51, 12 bit, big-endian, i-signal-type=PRIMITIVE, init-value=constant-reference=Init_CAN3_Rr_TorqMin, base-type=uint16, implementation-data-type=uint16, transfer-property=PENDING
          signal CAN3_Rr_UdcMax: start 71, 12 bit, big-endian, i-signal-type=PRIMITIVE, init-value=constant-reference=Init_CAN3_Rr_UdcMax, base-type=uint16, implementation-data-type=uint16, transfer-property=PENDING
          signal CAN3_Rr_UdcMin: start 75, 12 bit, big-endian, i-signal-type=PRIMITIVE, init-value=constant-reference=Init_CAN3_Rr_UdcMin, base-type=uint16, implementation-data-type=uint16, transfer-property=PENDING
      frame CAN3_MCU_F1: id 0x196, frame-length=32, can-addressing-mode=STANDARD, can-fd-frame-support=true, can-frame-rx-behavior=CAN-FD, can-frame-tx-behavior=CAN-FD
        pdu CAN3_MCU_F1: length=32, minimum-delay=0.0, transmission-mode-true-timing=cyclic-timing=time-period=0.01, unused-bit-pattern=0
          mapping CAN3_SG_MCU_F1: i-signal-group=CAN3_SG_MCU_F1, start-position=0, transfer-property=PENDING
          signal CAN3_Fr_ActvDmpDisabSta: start 201, 1 bit, big-endian, i-signal-type=PRIMITIVE, init-value=constant-reference=Init_CAN3_Fr_ActvDmpDisabSta, base-type=uint8, implementation-data-type=uint8, transfer-property=PENDING
          signal CAN3_Fr_EDUDrtSta: start 202, 1 bit, big-endian, i-signal-type=PRIMITIVE, init-value=constant-reference=Init_CAN3_Fr_EDUDrtSta, base-type=uint8, implementation-data-type=uint8, transfer-property=PENDING
          signal CAN3_Fr_EDUOpratingSta: start 245, 1 bit, big-endian, i-signal-type=PRIMITIVE, init-value=constant-reference=Init_CAN3_Fr_EDUOpratingSta, base-type=uint8, implementation-data-type=uint8, transfer-property=PENDING
          signal CAN3_Fr_EDURealTMTq: start 227, 12 bit, big-endian, i-signal-type=PRIMITIVE, init-value=constant-reference=Init_CAN3_Fr_EDURealTMTq, base-type=uint16, implementation-data-type=uint16, transfer-property=PENDING
          signal CAN3_Fr_EDURotateDirction: start 247, 2 bit, big-endian, i-signal-type=PRIMITIVE, init-value=constant-reference=Init_CAN3_Fr_EDURotateDirction, base-type=uint8, implementation-data-type=uint8, transfer-property=PENDING
          signal CAN3_Fr_EDUTqReqFbk: start 243, 12 bit, big-endian, i-signal-type=PRIMITIVE, init-value=constant-reference=Init_CAN3_Fr_EDUTqReqFbk, base-type=uint16, implementation-data-type=uint16, transfer-property=PENDING
          signal CAN3_Fr_MCU1Chksum: start 7, 8 bit, big-endian, i-signal-type=PRIMITIVE, init-value=constant-reference=Init_CAN3_Fr_MCU1Chksum, base-type=uint8, implementation-data-type=uint8, transfer-property=PENDING
          signal CAN3_Fr_MCU1RolCnt: start 15, 4 bit, big-endian, i-signal-type=PRIMITIVE, init-value=constant-reference=Init_CAN3_Fr_MCU1RolCnt, base-type=uint8, implementation-data-type=uint8, transfer-property=PENDING
          signal CAN3_Fr_MCUBAT: start 71, 8 bit, big-endian, i-signal-type=PRIMITIVE, init-value=constant-reference=Init_CAN3_Fr_MCUBAT, base-type=uint8, implementation-data-type=uint8, transfer-property=PENDING
          signal CAN3_Fr_MCUDCBusCurr: start 174, 15 bit, big-endian, i-signal-type=PRIMITIVE, init-value=constant-reference=Init_CAN3_Fr_MCUDCBusCurr, base-type=uint16, implementation-data-type=uint16, transfer-property=PENDING
          signal CAN3_Fr_MCUDCBusVolt: start 191, 16 bit, big-endian, i-signal-type=PRIMITIVE, init-value=constant-reference=Init_CAN3_Fr_MCUDCBusVolt, base-type=uint16, implementation-data-type=uint16, transfer-property=PENDING
          signal CAN3_Fr_MCUDischrgSta: start 203, 1 bit, big-endian, i-signal-type=PRIMITIVE, init-value=constant-reference=Init_CAN3_Fr_MCUDischrgSta, base-type=uint8, implementation-data-type=uint8, transfer-property=PENDING
          signal CAN3_Fr_MCUEnaSta: start 244, 1 bit, big-endian, i-signal-type=PRIMITIVE, init-value=constant-reference=Init_CAN3_Fr_MCUEnaSta, base-type=uint8, implementation-data-type=uint8, transfer-property=PENDING
          signal CAN3_Fr_MCUErr: start 143, 8 bit, big-endian, i-signal-type=PRIMITIVE, init-value=constant-reference=Init_CAN3_Fr_MCUErr, base-type=uint8, implementation-data-type=uint8, transfer-property=PENDING
          signal CAN3_Fr_MCUIGN_sta: start 72, 1 bit, big-endian, i-signal-type=PRIMITIVE, init-value=constant-reference=Init_CAN3_Fr_MCUIGN_sta, base-type=uint8, implementation-data-type=uint8, transfer-property=PENDING
          signal CAN3_Fr_MCUReady: start 11, 1 bit, big-endian, i-signal-type=PRIMITIVE, init-value=constant-reference=Init_CAN3_Fr_MCUReady, base-type=uint8, implementation-data-type=uint8, transfer-property=PENDING
          signal CAN3_Fr_MCUReady4Pre: start 200, 1 bit, big-endian, i-signal-type=PRIMITIVE, init-value=constant-reference=Init_CAN3_Fr_MCUReady4Pre, base-type=uint8, implementation-data-type=uint8, transfer-property=PENDING
          signal CAN3_Fr_MCUSysSta: start 59, 4 bit, big-endian, i-signal-type=PRIMITIVE, init-value=constant-reference=Init_CAN3_Fr_MCUSysSta, base-type=uint8, implementation-data-type=uint8, transfer-property=PENDING
          signal CAN3_Fr_MCUTemp: start 167, 9 bit, big-endian, i-signal-type=PRIMITIVE, init-value=constant-reference=Init_CAN3_Fr_MCUTemp, base-type=uint16, implementation-data-type=uint16, transfer-property=PENDING
          signal CAN3_Fr_MotorAvailTq: start 91, 12 bit, big-endian, i-signal-type=PRIMITIVE, init-value=constant-reference=Init_CAN3_Fr_MotorAvailTq, base-type=uint16, implementation-data-type=uint16, transfer-property=PENDING
          signal CAN3_Fr_RegenAvailTq: start 87, 12 bit, big-endian, i-signal-type=PRIMITIVE, init-value=constant-reference=Init_CAN3_Fr_RegenAvailTq, base-type=uint16, implementation-data-type=uint16, transfer-property=PENDING
          signal CAN3_Fr_Reserved_bits: start 79, 7 bit, big-endian, i-signal-type=PRIMITIVE, init-value=constant-reference=Init_CAN3_Fr_Reserved_bits, base-type=uint8, implementation-data-type=uint8, transfer-property=PENDING
          signal CAN3_Fr_TMSpd: start 215, 16 bit, big-endian, i-signal-type=PRIMITIVE, init-value=constant-reference=Init_CAN3_Fr_TMSpd, base-type=uint16, implementation-data-type=uint16, transfer-property=PENDING
          signal CAN3_Fr_TMTemp: start 144, 9 bit, big-endian, i-signal-type=PRIMITIVE, init-value=constant-reference=Init_CAN3_Fr_TMTemp, base-type=uint16, implementation-data-type=uint16, transfer-property=PENDING
          signal CAN3_Fr_TMid: start 126, 15 bit, big-endian, i-signal-type=PRIMITIVE, init-value=constant-reference=Init_CAN3_Fr_TMid, base-type=uint16, implementation-data-type=uint16, transfer-property=PENDING
          signal CAN3_Fr_TMiq: start 110, 15 bit, big-endian, i-signal-type=PRIMITIVE, init-value=constant-reference=Init_CAN3_Fr_TMiq, base-type=uint16, implementation-data-type=uint16, transfer-property=PENDING
          signal CAN3_MCUWarn_F: start 10, 3 bit, big-endian, i-signal-type=PRIMITIVE, init-value=constant-reference=Init_CAN3_MCUWarn_F, base-type=uint8, implementation-data-type=uint8, transfer-property=PENDING
      frame CAN3_MCU_F2: id 0x198, frame-length=12, can-addressing-mode=STANDARD, can-fd-frame-support=true, can-frame-rx-behavior=CAN-FD, can-frame-tx-behavior=CAN-FD
        pdu CAN3_MCU_F2: length=12, minimum-delay=0.0, transmission-mode-true-timing=cyclic-timing=time-period=0.2, unused-bit-pattern=0
          mapping CAN3_SG_MCU_F2: i-signal-group=CAN3_SG_MCU_F2, start-position=0, transfer-property=PENDING
          signal CAN3_Fr_CoolanttempReq: start 24, 9 bit, big-endian, i-signal-type=PRIMITIVE, init-value=constant-reference=Init_CAN3_Fr_CoolanttempReq, base-type=uint16, implementation-data-type=uint16, transfer-property=PENDING
          signal CAN3_Fr_EOP_SpdSet: start 67, 12 bit, big-endian, i-signal-type=PRIMITIVE, init-value=constant-reference=Init_CAN3_Fr_EOP_SpdSet, base-type=uint16, implementation-data-type=uint16, transfer-property=PENDING
          signal CAN3_Fr_Failcode1: start 63, 8 bit, big-endian, i-signal-type=PRIMITIVE, init-value=constant-reference=Init_CAN3_Fr_Failcode1, base-type=uint8, implementation-data-type=uint8, transfer-property=PENDING
          signal CAN3_Fr_Failcode2: start 55, 8 bit, big-endian, i-signal-type=PRIMITIVE, init-value=constant-reference=Init_CAN3_Fr_Failcode2, base-type=uint8, implementation-data-type=uint8, transfer-property=PENDING
          signal CAN3_Fr_Failcodehistory1: start 41, 2 bit, big-endian, i-signal-type=PRIMITIVE, init-value=constant-reference=Init_CAN3_Fr_Failcodehistory1, base-type=uint8, implementation-data-type=uint8, transfer-property=PENDING
          signal CAN3_Fr_Failcodehistory2: start 43, 2 bit, big-endian, i-signal-type=PRIMITIVE, init-value=constant-reference=Init_CAN3_Fr_Failcodehistory2, base-type=uint8, implementation-data-type=uint8, transfer-property=PENDING
          signal CAN3_Fr_LLCTemp: start 80, 9 bit, big-endian, i-signal-type=PRIMITIVE, init-value=constant-reference=Init_CAN3_Fr_LLCTemp, base-type=uint16, implementation-data-type=uint16, transfer-property=PENDING
          signal CAN3_Fr_LLCflowReq: start 87, 6 bit, big-endian, i-signal-type=PRIMITIVE, init-value=constant-reference=Init_CAN3_Fr_LLCflowReq, base-type=uint8, implementation-data-type=uint8, transfer-property=PENDING
          signal CAN3_Fr_MCU2Chksum: start 7, 8 bit, big-endian, i-signal-type=PRIMITIVE, init-value=constant-reference=Init_CAN3_Fr_MCU2Chksum, base-type=uint8, implementation-data-type=uint8, transfer-property=PENDING
          signal CAN3_Fr_MCU2RolCnt: start 15, 4 bit, big-endian, i-signal-type=PRIMITIVE, init-value=constant-reference=Init_CAN3_Fr_MCU2RolCnt, base-type=uint8, implementation-data-type=uint8, transfer-property=PENDING
          signal CAN3_Fr_MCUTempWarn: start 47, 2 bit, big-endian, i-signal-type=PRIMITIVE, init-value=constant-reference=Init_CAN3_Fr_MCUTempWarn, base-type=uint8, implementation-data-type=uint8, transfer-property=PENDING
          signal CAN3_Fr_TMTempWarn: start 45, 2 bit, big-endian, i-signal-type=PRIMITIVE, init-value=constant-reference=Init_CAN3_Fr_TMTempWarn, base-type=uint8, implementation-data-type=uint8, transfer-property=PENDING
          signal CAN3_MCU_F_ResetCnt_Sta: start 23, 8 bit, big-endian, i-signal-type=PRIMITIVE, init-value=constant-reference=Init_CAN3_MCU_F_ResetCnt_Sta, base-type=uint8, implementation-data-type=uint8, transfer-property=PENDING
      frame CAN3_MCU_R1: id 0x192, frame-length=32, can-addressing-mode=STANDARD, can-fd-frame-support=true, can-frame-rx-behavior=CAN-FD, can-frame-tx-behavior=CAN-FD
        pdu CAN3_MCU_R1: length=32, minimum-delay=0.0, transmission-mode-true-timing=cyclic-timing=time-period=0.01, unused-bit-pattern=0
          mapping CAN3_SG_MCU_R1: i-signal-group=CAN3_SG_MCU_R1, start-position=0, transfer-property=PENDING
          signal CAN3_MCUWarn_R: start 10, 3 bit, big-endian, i-signal-type=PRIMITIVE, init-value=constant-reference=Init_CAN3_MCUWarn_R, base-type=uint8, implementation-data-type=uint8, transfer-property=PENDING
          signal CAN3_Rr_ActvDmpDisabSta: start 201, 1 bit, big-endian, i-signal-type=PRIMITIVE, init-value=constant-reference=Init_CAN3_Rr_ActvDmpDisabSta, base-type=uint8, implementation-data-type=uint8, transfer-property=PENDING
          signal CAN3_Rr_EDUDrtSta: start 202, 1 bit, big-endian, i-signal-type=PRIMITIVE, init-value=constant-reference=Init_CAN3_Rr_EDUDrtSta, base-type=uint8, implementation-data-type=uint8, transfer-property=PENDING
          signal CAN3_Rr_EDUOpratingSta: start 245, 1 bit, big-endian, i-signal-type=PRIMITIVE, init-value=constant-reference=Init_CAN3_Rr_EDUOpratingSta, base-type=uint8, implementation-data-type=uint8, transfer-property=PENDING
          signal CAN3_Rr_EDURealTMTq: start 227, 12 bit, big-endian, i-signal-type=PRIMITIVE, init-value=constant-reference=Init_CAN3_Rr_EDURealTMTq, base-type=uint16, implementation-data-type=uint16, transfer-property=PENDING
          signal CAN3_Rr_EDURotateDirction: start 247, 2 bit, big-endian, i-signal-type=PRIMITIVE, init-value=constant-reference=Init_CAN3_Rr_EDURotateDirction, base-type=uint8, implementation-data-type=uint8, transfer-property=PENDING
          signal CAN3_Rr_EDUTqReqFbk: start 243, 12 bit, big-endian, i-signal-type=PRIMITIVE, init-value=constant-reference=Init_CAN3_Rr_EDUTqReqFbk, base-type=uint16, implementation-data-type=uint16, transfer-property=PENDING
          signal CAN3_Rr_MCU1Chksum: start 7, 8 bit, big-endian, i-signal-type=PRIMITIVE, init-value=constant-reference=Init_CAN3_Rr_MCU1Chksum, base-type=uint8, implementation-data-type=uint8, transfer-property=PENDING
          signal CAN3_Rr_MCU1RolCnt: start 15, 4 bit, big-endian, i-signal-type=PRIMITIVE, init-value=constant-reference=Init_CAN3_Rr_MCU1RolCnt, base-type=uint8, implementation-data-type=uint8, transfer-property=PENDING
          signal CAN3_Rr_MCUBAT: start 71, 8 bit, big-endian, i-signal-type=PRIMITIVE, init-value=constant-reference=Init_CAN3_Rr_MCUBAT, base-type=uint8, implementation-data-type=uint8, transfer-property=PENDING
          signal CAN3_Rr_MCUDCBusCurr: start 174, 15 bit, big-endian, i-signal-type=PRIMITIVE, init-value=constant-reference=Init_CAN3_Rr_MCUDCBusCurr, base-type=uint16, implementation-data-type=uint16, transfer-property=PENDING
          signal CAN3_Rr_MCUDCBusVolt: start 191, 16 bit, big-endian, i-signal-type=PRIMITIVE, init-value=constant-reference=Init_CAN3_Rr_MCUDCBusVolt, base-type=uint16, implementation-data-type=uint16, transfer-property=PENDING
          signal CAN3_Rr_MCUDischrgSta: start 203, 1 bit, big-endian, i-signal-type=PRIMITIVE, init-value=constant-reference=Init_CAN3_Rr_MCUDischrgSta, base-type=uint8, implementation-data-type=uint8, transfer-property=PENDING
          signal CAN3_Rr_MCUEnaSta: start 244, 1 bit, big-endian, i-signal-type=PRIMITIVE, init-value=constant-reference=Init_CAN3_Rr_MCUEnaSta, base-type=uint8, implementation-data-type=uint8, transfer-property=PENDING
          signal CAN3_Rr_MCUErr: start 143, 8 bit, big-endian, i-signal-type=PRIMITIVE, init-value=constant-reference=Init_CAN3_Rr_MCUErr, base-type=uint8, implementation-data-type=uint8, transfer-property=PENDING
          signal CAN3_Rr_MCUIGN_sta: start 72, 1 bit, big-endian, i-signal-type=PRIMITIVE, init-value=constant-reference=Init_CAN3_Rr_MCUIGN_sta, base-type=uint8, implementation-data-type=uint8, transfer-property=PENDING
          signal CAN3_Rr_MCUReady: start 207, 1 bit, big-endian, i-signal-type=PRIMITIVE, init-value=constant-reference=Init_CAN3_Rr_MCUReady, base-type=uint8, implementation-data-type=uint8, transfer-property=PENDING
          signal CAN3_Rr_MCUReady4Pre: start 200, 1 bit, big-endian, i-signal-type=PRIMITIVE, init-value=constant-reference=Init_CAN3_Rr_MCUReady4Pre, base-type=uint8, implementation-data-type=uint8, transfer-property=PENDING
          signal CAN3_Rr_MCUSysSta: start 59, 4 bit, big-endian, i-signal-type=PRIMITIVE, init-value=constant-reference=Init_CAN3_Rr_MCUSysSta, base-type=uint8, implementation-data-type=uint8, transfer-property=PENDING
          signal CAN3_Rr_MCUTemp: start 167, 9 bit, big-endian, i-signal-type=PRIMITIVE, init-value=constant-reference=Init_CAN3_Rr_MCUTemp, base-type=uint16, implementation-data-type=uint16, transfer-property=PENDING
          signal CAN3_Rr_MotorAvailTq: start 91, 12 bit, big-endian, i-signal-type=PRIMITIVE, init-value=constant-reference=Init_CAN3_Rr_MotorAvailTq, base-type=uint16, implementation-data-type=uint16, transfer-property=PENDING
          signal CAN3_Rr_RegenAvailTq: start 87, 12 bit, big-endian, i-signal-type=PRIMITIVE, init-value=constant-reference=Init_CAN3_Rr_RegenAvailTq, base-type=uint16, implementation-data-type=uint16, transfer-property=PENDING
          signal CAN3_Rr_Reserved_bits: start 79, 7 bit, big-endian, i-signal-type=PRIMITIVE, init-value=constant-reference=Init_CAN3_Rr_Reserved_bits, base-type=uint8, implementation-data-type=uint8, transfer-property=PENDING
          signal CAN3_Rr_TMSpd: start 215, 16 bit, big-endian, i-signal-type=PRIMITIVE, init-value=constant-reference=Init_CAN3_Rr_TMSpd, base-type=uint16, implementation-data-type=uint16, transfer-property=PENDING
          signal CAN3_Rr_TMTemp: start 144, 9 bit, big-endian, i-signal-type=PRIMITIVE, init-value=constant-reference=Init_CAN3_Rr_TMTemp, base-type=uint16, implementation-data-type=uint16, transfer-property=PENDING
          signal CAN3_Rr_TMid: start 126, 15 bit, big-endian, i-signal-type=PRIMITIVE, init-value=constant-reference=Init_CAN3_Rr_TMid, base-type=uint16, implementation-data-type=uint16, transfer-property=PENDING
          signal CAN3_Rr_TMiq: start 110, 15 bit, big-endian, i-signal-type=PRIMITIVE, init-value=constant-reference=Init_CAN3_Rr_TMiq, base-type=uint16, implementation-data-type=uint16, transfer-property=PENDING
      frame CAN3_MCU_R2: id 0x19C, frame-length=12, can-addressing-mode=STANDARD, can-fd-frame-support=true, can-frame-rx-behavior=CAN-FD, can-frame-tx-behavior=CAN-FD
        pdu CAN3_MCU_R2: length=12, minimum-delay=0.0, transmission-mode-true-timing=cyclic-timing=time-period=0.2, unused-bit-pattern=0
          mapping CAN3_SG_MCU_R2: i-signal-group=CAN3_SG_MCU_R2, start-position=0, transfer-property=PENDING
          signal CAN3_MCU_R_ResetCnt_Sta: start 23, 8 bit, big-endian, i-signal-type=PRIMITIVE, init-value=constant-reference=Init_CAN3_MCU_R_ResetCnt_Sta, base-type=uint8, implementation-data-type=uint8, transfer-property=PENDING
          signal CAN3_Rr_CoolanttempReq: start 24, 9 bit, big-endian, i-signal-type=PRIMITIVE, init-value=constant-reference=Init_CAN3_Rr_CoolanttempReq, base-type=uint16, implementation-data-type=uint16, transfer-property=PENDING
          signal CAN3_Rr_EOP_SpdSet: start 67, 12 bit, big-endian, i-signal-type=PRIMITIVE, init-value=constant-reference=Init_CAN3_Rr_EOP_SpdSet, base-type=uint16, implementation-data-type=uint16, transfer-property=PENDING
          signal CAN3_Rr_Failcode1: start 63, 8 bit, big-endian, i-signal-type=PRIMITIVE, init-value=constant-reference=Init_CAN3_Rr_Failcode1, base-type=uint8, implementation-data-type=uint8, transfer-property=PENDING
          signal CAN3_Rr_Failcode2: start 55, 8 bit, big-endian, i-signal-type=PRIMITIVE, init-value=constant-reference=Init_CAN3_Rr_Failcode2, base-type=uint8, implementation-data-type=uint8, transfer-property=PENDING
          signal CAN3_Rr_Failcodehistory1: start 41, 2 bit, big-endian, i-signal-type=PRIMITIVE, init-value=constant-reference=Init_CAN3_Rr_Failcodehistory1, base-type=uint8, implementation-data-type=uint8, transfer-property=PENDING
          signal CAN3_Rr_Failcodehistory2: start 43, 2 bit, big-endian, i-signal-type=PRIMITIVE, init-value=constant-reference=Init_CAN3_Rr_Failcodehistory2, base-type=uint8, implementation-data-type=uint8, transfer-property=PENDING
          signal CAN3_Rr_LLCTemp: start 80, 9 bit, big-endian, i-signal-type=PRIMITIVE, init-value=constant-reference=Init_CAN3_Rr_LLCTemp, base-type=uint16, implementation-data-type=uint16, transfer-property=PENDING
          signal CAN3_Rr_LLCflowReq: start 87, 6 bit, big-endian, i-signal-type=PRIMITIVE, init-value=constant-reference=Init_CAN3_Rr_LLCflowReq, base-type=uint8, implementation-data-type=uint8, transfer-property=PENDING
          signal CAN3_Rr_MCU2Chksum: start 7, 8 bit, big-endian, i-signal-type=PRIMITIVE, init-value=constant-reference=Init_CAN3_Rr_MCU2Chksum, base-type=uint8, implementation-data-type=uint8, transfer-property=PENDING
          signal CAN3_Rr_MCU2RolCnt: start 15, 4 bit, big-endian, i-signal-type=PRIMITIVE, init-value=constant-reference=Init_CAN3_Rr_MCU2RolCnt, base-type=uint8, implementation-data-type=uint8, transfer-property=PENDING
          signal CAN3_Rr_MCUTempWarn: start 47, 2 bit, big-endian, i-signal-type=PRIMITIVE, init-value=constant-reference=Init_CAN3_Rr_MCUTempWarn, base-type=uint8, implementation-data-type=uint8, transfer-property=PENDING
          signal CAN3_Rr_TMTempWarn: start 45, 2 bit, big-endian, i-signal-type=PRIMITIVE, init-value=constant-reference=Init_CAN3_Rr_TMTempWarn, base-type=uint8, implementation-data-type=uint8, transfer-property=PENDING
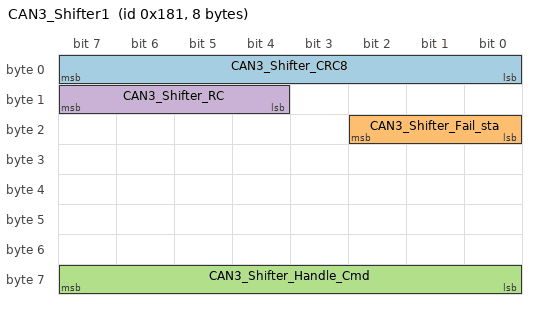
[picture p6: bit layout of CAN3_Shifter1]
      frame CAN3_Shifter1: id 0x181, frame-length=8, can-addressing-mode=STANDARD, can-fd-frame-support=true, can-frame-rx-behavior=CAN-FD, can-frame-tx-behavior=CAN-FD
        pdu CAN3_Shifter1: length=8, minimum-delay=0.0, transmission-mode-true-timing={cyclic-timing=time-period=0.1, event-controlled-timing={number-of-repetitions=0, repetition-period=0.01}}, unused-bit-pattern=0
          mapping CAN3_SG_Shifter1: i-signal-group=CAN3_SG_Shifter1, start-position=0, transfer-property=TRIGGERED-ON-CHANGE
          signal CAN3_Shifter_CRC8: start 7, 8 bit, big-endian, i-signal-type=PRIMITIVE, init-value=constant-reference=Init_CAN3_Shifter_CRC8, base-type=uint8, implementation-data-type=uint8, transfer-property=TRIGGERED-ON-CHANGE
          signal CAN3_Shifter_Fail_sta: start 18, 3 bit, big-endian, i-signal-type=PRIMITIVE, init-value=constant-reference=Init_CAN3_Shifter_Fail_sta, base-type=uint8, implementation-data-type=uint8, transfer-property=TRIGGERED-ON-CHANGE
          signal CAN3_Shifter_Handle_Cmd: start 63, 8 bit, big-endian, i-signal-type=PRIMITIVE, init-value=constant-reference=Init_CAN3_Shifter_Handle_Cmd, base-type=uint8, implementation-data-type=uint8, transfer-property=TRIGGERED-ON-CHANGE
          signal CAN3_Shifter_RC: start 15, 4 bit, big-endian, i-signal-type=PRIMITIVE, init-value=constant-reference=Init_CAN3_Shifter_RC, base-type=uint8, implementation-data-type=uint8, transfer-property=TRIGGERED-ON-CHANGE
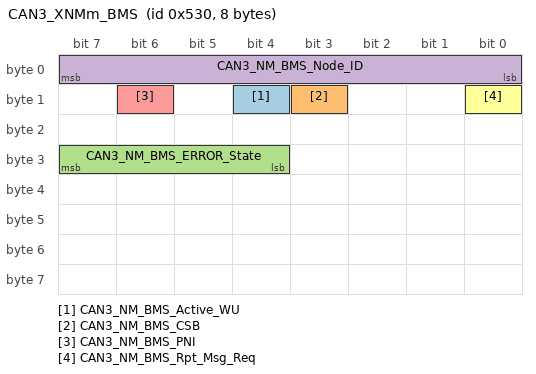
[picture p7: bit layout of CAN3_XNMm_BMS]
      frame CAN3_XNMm_BMS: id 0x530, frame-length=8, can-addressing-mode=STANDARD, can-fd-frame-support=false, can-frame-rx-behavior=CAN-20, can-frame-tx-behavior=CAN-20
        pdu CAN3_XNMm_BMS: length=8, minimum-delay=0.0, transmission-mode-true-timing=cyclic-timing=time-period=0.7, unused-bit-pattern=0
          mapping CAN3_SG_XNMm_BMS: i-signal-group=CAN3_SG_XNMm_BMS, start-position=0, transfer-property=PENDING
          signal CAN3_NM_BMS_Active_WU: start 12, 1 bit, big-endian, i-signal-type=PRIMITIVE, init-value=constant-reference=Init_CAN3_NM_BMS_Active_WU, base-type=uint8, implementation-data-type=uint8, transfer-property=PENDING
          signal CAN3_NM_BMS_CSB: start 11, 1 bit, big-endian, i-signal-type=PRIMITIVE, init-value=constant-reference=Init_CAN3_NM_BMS_CSB, base-type=uint8, implementation-data-type=uint8, transfer-property=PENDING
          signal CAN3_NM_BMS_ERROR_State: start 31, 4 bit, big-endian, i-signal-type=PRIMITIVE, init-value=constant-reference=Init_CAN3_NM_BMS_ERROR_State, base-type=uint8, implementation-data-type=uint8, transfer-property=PENDING
          signal CAN3_NM_BMS_Node_ID: start 7, 8 bit, big-endian, i-signal-type=PRIMITIVE, init-value=constant-reference=Init_CAN3_NM_BMS_Node_ID, base-type=uint8, implementation-data-type=uint8, transfer-property=PENDING
          signal CAN3_NM_BMS_PNI: start 14, 1 bit, big-endian, i-signal-type=PRIMITIVE, init-value=constant-reference=Init_CAN3_NM_BMS_PNI, base-type=uint8, implementation-data-type=uint8, transfer-property=PENDING
          signal CAN3_NM_BMS_Rpt_Msg_Req: start 8, 1 bit, big-endian, i-signal-type=PRIMITIVE, init-value=constant-reference=Init_CAN3_NM_BMS_Rpt_Msg_Req, base-type=uint8, implementation-data-type=uint8, transfer-property=PENDING
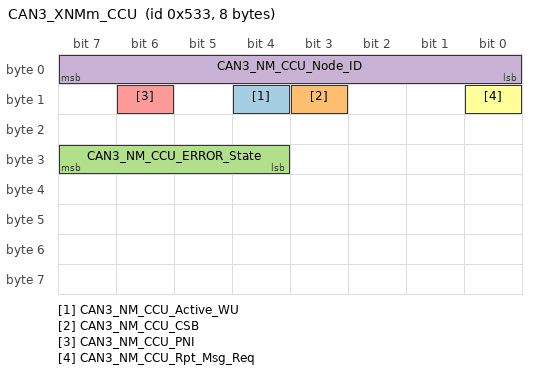
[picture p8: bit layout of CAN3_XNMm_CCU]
      frame CAN3_XNMm_CCU: id 0x533, frame-length=8, can-addressing-mode=STANDARD, can-fd-frame-support=false, can-frame-rx-behavior=CAN-20, can-frame-tx-behavior=CAN-20
        pdu CAN3_XNMm_CCU: length=8, minimum-delay=0.0, transmission-mode-true-timing=cyclic-timing=time-period=0.7, unused-bit-pattern=0
          mapping CAN3_SG_XNMm_CCU: i-signal-group=CAN3_SG_XNMm_CCU, start-position=0, transfer-property=PENDING
          signal CAN3_NM_CCU_Active_WU: start 12, 1 bit, big-endian, i-signal-type=PRIMITIVE, init-value=constant-reference=Init_CAN3_NM_CCU_Active_WU, base-type=uint8, implementation-data-type=uint8, transfer-property=PENDING
          signal CAN3_NM_CCU_CSB: start 11, 1 bit, big-endian, i-signal-type=PRIMITIVE, init-value=constant-reference=Init_CAN3_NM_CCU_CSB, base-type=uint8, implementation-data-type=uint8, transfer-property=PENDING
          signal CAN3_NM_CCU_ERROR_State: start 31, 4 bit, big-endian, i-signal-type=PRIMITIVE, init-value=constant-reference=Init_CAN3_NM_CCU_ERROR_State, base-type=uint8, implementation-data-type=uint8, transfer-property=PENDING
          signal CAN3_NM_CCU_Node_ID: start 7, 8 bit, big-endian, i-signal-type=PRIMITIVE, init-value=constant-reference=Init_CAN3_NM_CCU_Node_ID, base-type=uint8, implementation-data-type=uint8, transfer-property=PENDING
          signal CAN3_NM_CCU_PNI: start 14, 1 bit, big-endian, i-signal-type=PRIMITIVE, init-value=constant-reference=Init_CAN3_NM_CCU_PNI, base-type=uint8, implementation-data-type=uint8, transfer-property=PENDING
          signal CAN3_NM_CCU_Rpt_Msg_Req: start 8, 1 bit, big-endian, i-signal-type=PRIMITIVE, init-value=constant-reference=Init_CAN3_NM_CCU_Rpt_Msg_Req, base-type=uint8, implementation-data-type=uint8, transfer-property=PENDING
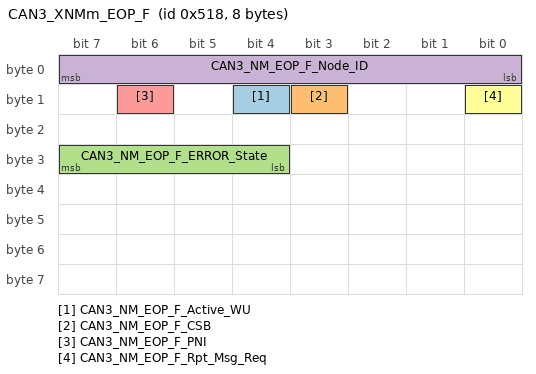
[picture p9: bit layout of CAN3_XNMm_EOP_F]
      frame CAN3_XNMm_EOP_F: id 0x518, frame-length=8, can-addressing-mode=STANDARD, can-fd-frame-support=false, can-frame-rx-behavior=CAN-20, can-frame-tx-behavior=CAN-20
        pdu CAN3_XNMm_EOP_F: length=8, minimum-delay=0.0, transmission-mode-true-timing=cyclic-timing=time-period=0.7, unused-bit-pattern=0
          mapping CAN3_SG_XNMm_EOP_F: i-signal-group=CAN3_SG_XNMm_EOP_F, start-position=0, transfer-property=PENDING
          signal CAN3_NM_EOP_F_Active_WU: start 12, 1 bit, big-endian, i-signal-type=PRIMITIVE, init-value=constant-reference=Init_CAN3_NM_EOP_F_Active_WU, base-type=uint8, implementation-data-type=uint8, transfer-property=PENDING
          signal CAN3_NM_EOP_F_CSB: start 11, 1 bit, big-endian, i-signal-type=PRIMITIVE, init-value=constant-reference=Init_CAN3_NM_EOP_F_CSB, base-type=uint8, implementation-data-type=uint8, transfer-property=PENDING
          signal CAN3_NM_EOP_F_ERROR_State: start 31, 4 bit, big-endian, i-signal-type=PRIMITIVE, init-value=constant-reference=Init_CAN3_NM_EOP_F_ERROR_State, base-type=uint8, implementation-data-type=uint8, transfer-property=PENDING
          signal CAN3_NM_EOP_F_Node_ID: start 7, 8 bit, big-endian, i-signal-type=PRIMITIVE, init-value=constant-reference=Init_CAN3_NM_EOP_F_Node_ID, base-type=uint8, implementation-data-type=uint8, transfer-property=PENDING
          signal CAN3_NM_EOP_F_PNI: start 14, 1 bit, big-endian, i-signal-type=PRIMITIVE, init-value=constant-reference=Init_CAN3_NM_EOP_F_PNI, base-type=uint8, implementation-data-type=uint8, transfer-property=PENDING
          signal CAN3_NM_EOP_F_Rpt_Msg_Req: start 8, 1 bit, big-endian, i-signal-type=PRIMITIVE, init-value=constant-reference=Init_CAN3_NM_EOP_F_Rpt_Msg_Req, base-type=uint8, implementation-data-type=uint8, transfer-property=PENDING
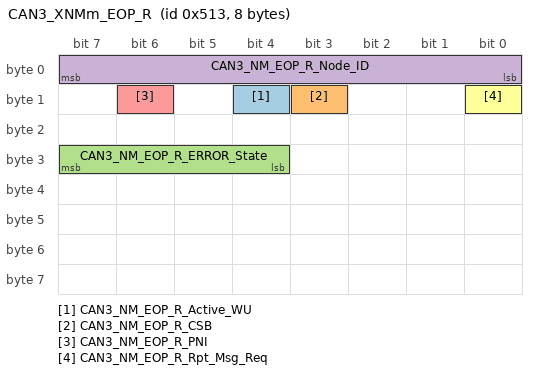
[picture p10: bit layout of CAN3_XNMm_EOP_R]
      frame CAN3_XNMm_EOP_R: id 0x513, frame-length=8, can-addressing-mode=STANDARD, can-fd-frame-support=false, can-frame-rx-behavior=CAN-20, can-frame-tx-behavior=CAN-20
        pdu CAN3_XNMm_EOP_R: length=8, minimum-delay=0.0, transmission-mode-true-timing=cyclic-timing=time-period=0.7, unused-bit-pattern=0
          mapping CAN3_SG_XNMm_EOP_R: i-signal-group=CAN3_SG_XNMm_EOP_R, start-position=0, transfer-property=PENDING
          signal CAN3_NM_EOP_R_Active_WU: start 12, 1 bit, big-endian, i-signal-type=PRIMITIVE, init-value=constant-reference=Init_CAN3_NM_EOP_R_Active_WU, base-type=uint8, implementation-data-type=uint8, transfer-property=PENDING
          signal CAN3_NM_EOP_R_CSB: start 11, 1 bit, big-endian, i-signal-type=PRIMITIVE, init-value=constant-reference=Init_CAN3_NM_EOP_R_CSB, base-type=uint8, implementation-data-type=uint8, transfer-property=PENDING
          signal CAN3_NM_EOP_R_ERROR_State: start 31, 4 bit, big-endian, i-signal-type=PRIMITIVE, init-value=constant-reference=Init_CAN3_NM_EOP_R_ERROR_State, base-type=uint8, implementation-data-type=uint8, transfer-property=PENDING
          signal CAN3_NM_EOP_R_Node_ID: start 7, 8 bit, big-endian, i-signal-type=PRIMITIVE, init-value=constant-reference=Init_CAN3_NM_EOP_R_Node_ID, base-type=uint8, implementation-data-type=uint8, transfer-property=PENDING
          signal CAN3_NM_EOP_R_PNI: start 14, 1 bit, big-endian, i-signal-type=PRIMITIVE, init-value=constant-reference=Init_CAN3_NM_EOP_R_PNI, base-type=uint8, implementation-data-type=uint8, transfer-property=PENDING
          signal CAN3_NM_EOP_R_Rpt_Msg_Req: start 8, 1 bit, big-endian, i-signal-type=PRIMITIVE, init-value=constant-reference=Init_CAN3_NM_EOP_R_Rpt_Msg_Req, base-type=uint8, implementation-data-type=uint8, transfer-property=PENDING
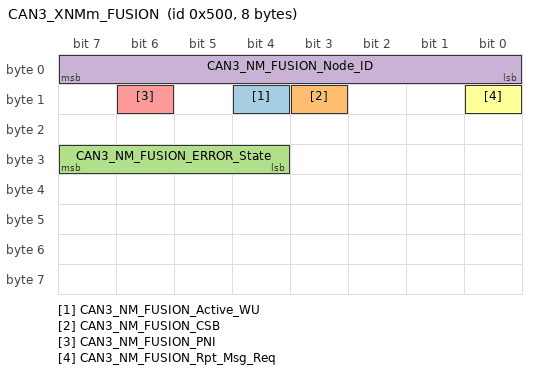
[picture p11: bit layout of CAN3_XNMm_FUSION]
      frame CAN3_XNMm_FUSION: id 0x500, frame-length=8, can-addressing-mode=STANDARD, can-fd-frame-support=false, can-frame-rx-behavior=CAN-20, can-frame-tx-behavior=CAN-20
        pdu CAN3_XNMm_FUSION: length=8, minimum-delay=0.0, transmission-mode-true-timing=cyclic-timing=time-period=0.7, unused-bit-pattern=0
          mapping CAN3_SG_XNMm_FUSION: i-signal-group=CAN3_SG_XNMm_FUSION, start-position=0, transfer-property=PENDING
          signal CAN3_NM_FUSION_Active_WU: start 12, 1 bit, big-endian, i-signal-type=PRIMITIVE, init-value=constant-reference=Init_CAN3_NM_FUSION_Active_WU, base-type=uint8, implementation-data-type=uint8, transfer-property=PENDING
          signal CAN3_NM_FUSION_CSB: start 11, 1 bit, big-endian, i-signal-type=PRIMITIVE, init-value=constant-reference=Init_CAN3_NM_FUSION_CSB, base-type=uint8, implementation-data-type=uint8, transfer-property=PENDING
          signal CAN3_NM_FUSION_ERROR_State: start 31, 4 bit, big-endian, i-signal-type=PRIMITIVE, init-value=constant-reference=Init_CAN3_NM_FUSION_ERROR_State, base-type=uint8, implementation-data-type=uint8, transfer-property=PENDING
          signal CAN3_NM_FUSION_Node_ID: start 7, 8 bit, big-endian, i-signal-type=PRIMITIVE, init-value=constant-reference=Init_CAN3_NM_FUSION_Node_ID, base-type=uint8, implementation-data-type=uint8, transfer-property=PENDING
          signal CAN3_NM_FUSION_PNI: start 14, 1 bit, big-endian, i-signal-type=PRIMITIVE, init-value=constant-reference=Init_CAN3_NM_FUSION_PNI, base-type=uint8, implementation-data-type=uint8, transfer-property=PENDING
          signal CAN3_NM_FUSION_Rpt_Msg_Req: start 8, 1 bit, big-endian, i-signal-type=PRIMITIVE, init-value=constant-reference=Init_CAN3_NM_FUSION_Rpt_Msg_Req, base-type=uint8, implementation-data-type=uint8, transfer-property=PENDING
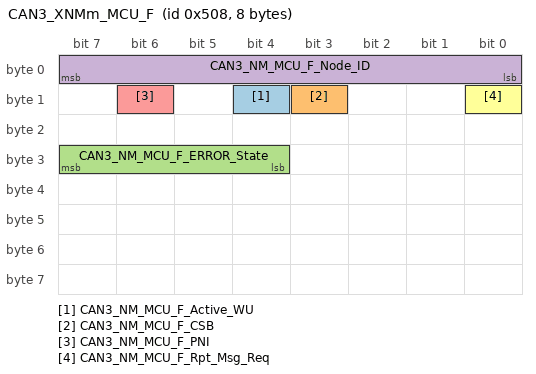
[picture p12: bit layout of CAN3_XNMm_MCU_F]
      frame CAN3_XNMm_MCU_F: id 0x508, frame-length=8, can-addressing-mode=STANDARD, can-fd-frame-support=false, can-frame-rx-behavior=CAN-20, can-frame-tx-behavior=CAN-20
        pdu CAN3_XNMm_MCU_F: length=8, minimum-delay=0.0, transmission-mode-true-timing=cyclic-timing=time-period=0.7, unused-bit-pattern=0
          mapping CAN3_SG_XNMm_MCU_F: i-signal-group=CAN3_SG_XNMm_MCU_F, start-position=0, transfer-property=PENDING
          signal CAN3_NM_MCU_F_Active_WU: start 12, 1 bit, big-endian, i-signal-type=PRIMITIVE, init-value=constant-reference=Init_CAN3_NM_MCU_F_Active_WU, base-type=uint8, implementation-data-type=uint8, transfer-property=PENDING
          signal CAN3_NM_MCU_F_CSB: start 11, 1 bit, big-endian, i-signal-type=PRIMITIVE, init-value=constant-reference=Init_CAN3_NM_MCU_F_CSB, base-type=uint8, implementation-data-type=uint8, transfer-property=PENDING
          signal CAN3_NM_MCU_F_ERROR_State: start 31, 4 bit, big-endian, i-signal-type=PRIMITIVE, init-value=constant-reference=Init_CAN3_NM_MCU_F_ERROR_State, base-type=uint8, implementation-data-type=uint8, transfer-property=PENDING
          signal CAN3_NM_MCU_F_Node_ID: start 7, 8 bit, big-endian, i-signal-type=PRIMITIVE, init-value=constant-reference=Init_CAN3_NM_MCU_F_Node_ID, base-type=uint8, implementation-data-type=uint8, transfer-property=PENDING
          signal CAN3_NM_MCU_F_PNI: start 14, 1 bit, big-endian, i-signal-type=PRIMITIVE, init-value=constant-reference=Init_CAN3_NM_MCU_F_PNI, base-type=uint8, implementation-data-type=uint8, transfer-property=PENDING
          signal CAN3_NM_MCU_F_Rpt_Msg_Req: start 8, 1 bit, big-endian, i-signal-type=PRIMITIVE, init-value=constant-reference=Init_CAN3_NM_MCU_F_Rpt_Msg_Req, base-type=uint8, implementation-data-type=uint8, transfer-property=PENDING
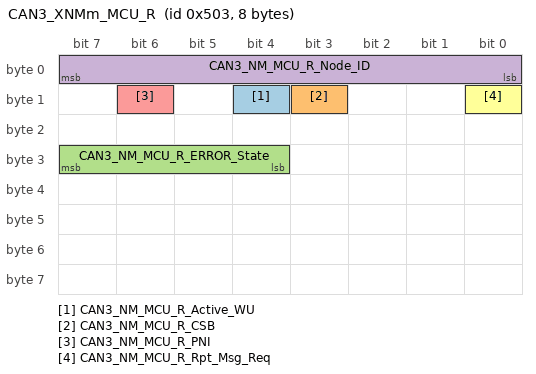
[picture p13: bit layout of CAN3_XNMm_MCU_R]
      frame CAN3_XNMm_MCU_R: id 0x503, frame-length=8, can-addressing-mode=STANDARD, can-fd-frame-support=false, can-frame-rx-behavior=CAN-20, can-frame-tx-behavior=CAN-20
        pdu CAN3_XNMm_MCU_R: length=8, minimum-delay=0.0, transmission-mode-true-timing=cyclic-timing=time-period=0.7, unused-bit-pattern=0
          mapping CAN3_SG_XNMm_MCU_R: i-signal-group=CAN3_SG_XNMm_MCU_R, start-position=0, transfer-property=PENDING
          signal CAN3_NM_MCU_R_Active_WU: start 12, 1 bit, big-endian, i-signal-type=PRIMITIVE, init-value=constant-reference=Init_CAN3_NM_MCU_R_Active_WU, base-type=uint8, implementation-data-type=uint8, transfer-property=PENDING
          signal CAN3_NM_MCU_R_CSB: start 11, 1 bit, big-endian, i-signal-type=PRIMITIVE, init-value=constant-reference=Init_CAN3_NM_MCU_R_CSB, base-type=uint8, implementation-data-type=uint8, transfer-property=PENDING
          signal CAN3_NM_MCU_R_ERROR_State: start 31, 4 bit, big-endian, i-signal-type=PRIMITIVE, init-value=constant-reference=Init_CAN3_NM_MCU_R_ERROR_State, base-type=uint8, implementation-data-type=uint8, transfer-property=PENDING
          signal CAN3_NM_MCU_R_Node_ID: start 7, 8 bit, big-endian, i-signal-type=PRIMITIVE, init-value=constant-reference=Init_CAN3_NM_MCU_R_Node_ID, base-type=uint8, implementation-data-type=uint8, transfer-property=PENDING
          signal CAN3_NM_MCU_R_PNI: start 14, 1 bit, big-endian, i-signal-type=PRIMITIVE, init-value=constant-reference=Init_CAN3_NM_MCU_R_PNI, base-type=uint8, implementation-data-type=uint8, transfer-property=PENDING
          signal CAN3_NM_MCU_R_Rpt_Msg_Req: start 8, 1 bit, big-endian, i-signal-type=PRIMITIVE, init-value=constant-reference=Init_CAN3_NM_MCU_R_Rpt_Msg_Req, base-type=uint8, implementation-data-type=uint8, transfer-property=PENDING
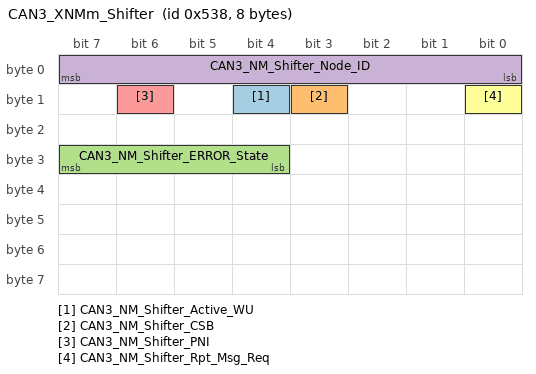
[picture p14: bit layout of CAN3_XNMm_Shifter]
      frame CAN3_XNMm_Shifter: id 0x538, frame-length=8, can-addressing-mode=STANDARD, can-fd-frame-support=false, can-frame-rx-behavior=CAN-20, can-frame-tx-behavior=CAN-20
        pdu CAN3_XNMm_Shifter: length=8, minimum-delay=0.0, transmission-mode-true-timing=cyclic-timing=time-period=0.7, unused-bit-pattern=0
          mapping CAN3_SG_XNMm_Shifter: i-signal-group=CAN3_SG_XNMm_Shifter, start-position=0, transfer-property=PENDING
          signal CAN3_NM_Shifter_Active_WU: start 12, 1 bit, big-endian, i-signal-type=PRIMITIVE, init-value=constant-reference=Init_CAN3_NM_Shifter_Active_WU, base-type=uint8, implementation-data-type=uint8, transfer-property=PENDING
          signal CAN3_NM_Shifter_CSB: start 11, 1 bit, big-endian, i-signal-type=PRIMITIVE, init-value=constant-reference=Init_CAN3_NM_Shifter_CSB, base-type=uint8, implementation-data-type=uint8, transfer-property=PENDING
          signal CAN3_NM_Shifter_ERROR_State: start 31, 4 bit, big-endian, i-signal-type=PRIMITIVE, init-value=constant-reference=Init_CAN3_NM_Shifter_ERROR_State, base-type=uint8, implementation-data-type=uint8, transfer-property=PENDING
          signal CAN3_NM_Shifter_Node_ID: start 7, 8 bit, big-endian, i-signal-type=PRIMITIVE, init-value=constant-reference=Init_CAN3_NM_Shifter_Node_ID, base-type=uint8, implementation-data-type=uint8, transfer-property=PENDING
          signal CAN3_NM_Shifter_PNI: start 14, 1 bit, big-endian, i-signal-type=PRIMITIVE, init-value=constant-reference=Init_CAN3_NM_Shifter_PNI, base-type=uint8, implementation-data-type=uint8, transfer-property=PENDING
          signal CAN3_NM_Shifter_Rpt_Msg_Req: start 8, 1 bit, big-endian, i-signal-type=PRIMITIVE, init-value=constant-reference=Init_CAN3_NM_Shifter_Rpt_Msg_Req, base-type=uint8, implementation-data-type=uint8, transfer-property=PENDING
